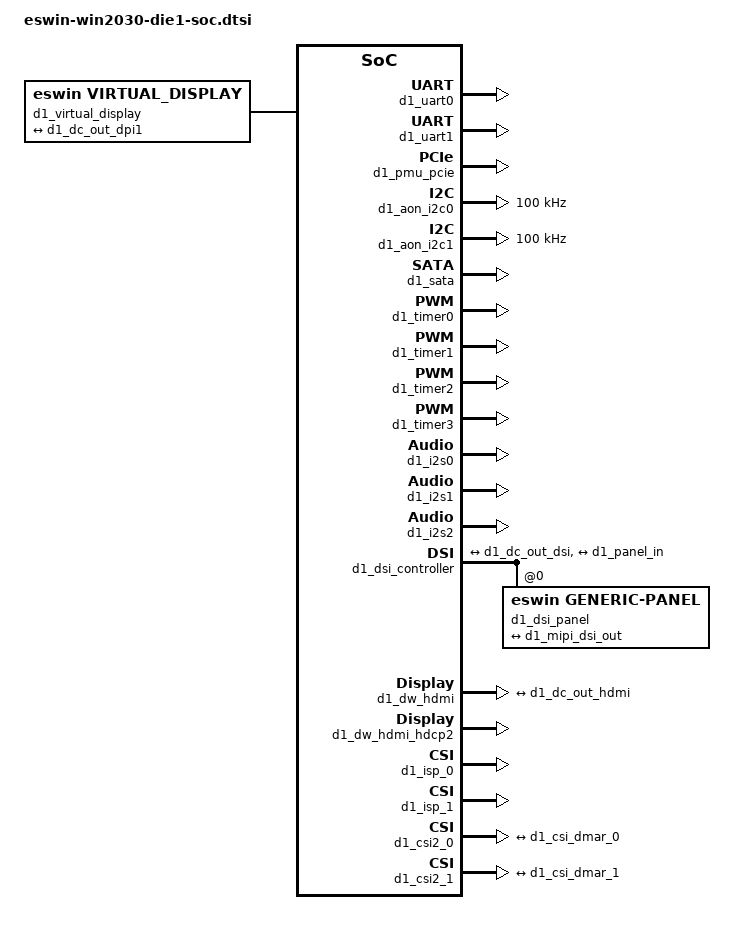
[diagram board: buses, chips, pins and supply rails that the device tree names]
// SPDX-License-Identifier: GPL-2.0
/*
 * Device Tree Include file for Die1 System peripherals of Eswin EIC770x family SoC.
 *
 * Copyright 2024, Beijing ESWIN Computing Technology Co., Ltd.. All rights reserved.
 * SPDX-License-Identifier: GPL-2.0
 *
 * This program is free software: you can redistribute it and/or modify
 * it under the terms of the GNU General Public License as published by
 * the Free Software Foundation, version 2.
 *
 * This program is distributed in the hope that it will be useful,
 * but WITHOUT ANY WARRANTY; without even the implied warranty of
 * MERCHANTABILITY or FITNESS FOR A PARTICULAR PURPOSE.  See the
 * GNU General Public License for more details.
 *
 * You should have received a copy of the GNU General Public License
 * along with this program.  If not, see <https://www.gnu.org/licenses/>.
 */

#include "eswin-win2030-arch-d2d.dtsi"


#include <dt-bindings/memory/eswin-win2030-sid.h>
#include <dt-bindings/mailbox/eswin-mailbox.h>
#include <dt-bindings/reset/eswin,win2030-syscrg.h>
#include <dt-bindings/clock/win2030-clock.h>
#include <dt-bindings/i2c/i2c.h>
#include <dt-bindings/interconnect/eswin,win2030.h>
#include <dt-bindings/power/eswin,eic770x-pmu.h>
#include <dt-bindings/thermal/thermal.h>

/ {
	d1_cpu_opp_table: opp-table1 {
		compatible = "operating-points-v2";
		opp-shared;

		opp-24000000 {
			opp-hz = /bits/ 64 <CLK_FREQ_24M>;
			opp-microvolt = <800000>;
			clock-latency-ns = <70000>;
		};
		opp-100000000 {
			opp-hz = /bits/ 64 <CLK_FREQ_100M>;
			opp-microvolt = <800000>;
			clock-latency-ns = <70000>;
		};
		opp-200000000 {
			opp-hz = /bits/ 64 <CLK_FREQ_200M>;
			opp-microvolt = <800000>;
			clock-latency-ns = <70000>;
		};
		opp-400000000 {
			opp-hz = /bits/ 64 <CLK_FREQ_400M>;
			opp-microvolt = <800000>;
			clock-latency-ns = <70000>;
		};
		opp-500000000 {
			opp-hz = /bits/ 64 <CLK_FREQ_500M>;
			opp-microvolt = <800000>;
			clock-latency-ns = <70000>;
		};
		opp-600000000 {
			opp-hz = /bits/ 64 <CLK_FREQ_600M>;
			opp-microvolt = <800000>;
			clock-latency-ns = <70000>;
		};
		opp-700000000 {
			opp-hz = /bits/ 64 <CLK_FREQ_700M>;
			opp-microvolt = <800000>;
			clock-latency-ns = <70000>;
		};
		opp-800000000 {
			opp-hz = /bits/ 64 <CLK_FREQ_800M>;
			opp-microvolt = <800000>;
			clock-latency-ns = <70000>;
		};
		opp-900000000 {
			opp-hz = /bits/ 64 <CLK_FREQ_900M>;
			opp-microvolt = <800000>;
			clock-latency-ns = <70000>;
		};
		opp-1000000000 {
			opp-hz = /bits/ 64 <CLK_FREQ_1000M>;
			opp-microvolt = <800000>;
			clock-latency-ns = <70000>;
		};
		opp-1200000000 {
			opp-hz = /bits/ 64 <CLK_FREQ_1200M>;
			opp-microvolt = <800000>;
			clock-latency-ns = <70000>;
		};
		opp-1300000000 {
			opp-hz = /bits/ 64 <CLK_FREQ_1300M>;
			opp-microvolt = <800000>;
			clock-latency-ns = <70000>;
		};
		opp-1400000000 {
			opp-hz = /bits/ 64 <CLK_FREQ_1400M>;
			opp-microvolt = <800000>;
			clock-latency-ns = <70000>;
		};
	};

	thermal-zones {
		d1_thermal0 {
			polling-delay-passive = <500>; /*ms*/
			polling-delay = <5000>; /*ms*/
			sustainable-power = <1200>; /*mW*/
			thermal-sensors = <&d1_pvt0>;

			trips {
				d1_threshold: trip-point0 {
					temperature = <60000>; /* DC*1000 */
					hysteresis = <1000>; /* DC*1000 */
					type = "passive";
				};
				d1_target: trip-point1 {
					temperature = <70000>;
					hysteresis = <1000>;
					type = "passive";
				};
				d1_crit: trip-point2 {
					temperature     = <110000>;
					hysteresis      = <0>;
					type            = "critical";
				};
			};

			cooling-maps {
				map0 {
					trip = <&d1_target>;
					contribution = <1024>;
					cooling-device =
						<&cpu_4 THERMAL_NO_LIMIT THERMAL_NO_LIMIT>,
						<&cpu_5 THERMAL_NO_LIMIT THERMAL_NO_LIMIT>,
						<&cpu_6 THERMAL_NO_LIMIT THERMAL_NO_LIMIT>,
						<&cpu_7 THERMAL_NO_LIMIT THERMAL_NO_LIMIT>;
				};
				map1 {
					trip = <&d1_target>;
					contribution = <1024>; /*TBD*/
					cooling-device = <&d1_npu THERMAL_NO_LIMIT THERMAL_NO_LIMIT>;
				};
				map2 {
					trip = <&d1_target>;
					contribution = <1024>; /*TBD*/
					cooling-device = <&d1_gpu THERMAL_NO_LIMIT THERMAL_NO_LIMIT>;
				};
			};
		};
	};
};

&SOC {
		d1_uart0: serial@0x70900000 {
			compatible = "snps,dw-apb-uart";
			reg = <0x0 0x70900000 0x0 0x10000>;
			clock-frequency = <LSPCLK_FREQ>;
			interrupt-parent = <&plic1>;
			interrupts = <UART0_INT>;
			reg-shift = <2>;
			reg-io-width = <4>;
			numa-node-id = <1>;
		};

		d1_uart1: serial@0x70910000 {
			compatible = "snps,dw-apb-uart";
			reg = <0x0 0x70910000 0x0 0x10000>;
			clock-frequency = <LSPCLK_FREQ>;
			interrupt-parent = <&plic1>;
			interrupts = <UART1_INT>;
			reg-shift = <2>;
			reg-io-width = <4>;
			numa-node-id = <1>;
		};

		d1_uart2: serial@0x70920000 {
			compatible = "snps,dw-apb-uart";
			reg = <0x0 0x70920000 0x0 0x10000>;
			clock-frequency = <LSPCLK_FREQ>;
			interrupt-parent = <&plic1>;
			interrupts = <UART2_INT>;
			reg-shift = <2>;
			reg-io-width = <4>;
			numa-node-id = <1>;
			status = "disabled";
		};

		d1_uart3: serial@0x70930000 {
			compatible = "snps,dw-apb-uart";
			reg = <0x0 0x70930000 0x0 0x10000>;
			clock-frequency = <LSPCLK_FREQ>;
			interrupt-parent = <&plic1>;
			interrupts = <UART3_INT>;
			reg-shift = <2>;
			reg-io-width = <4>;
			numa-node-id = <1>;
			status = "disabled";
		};

		d1_uart4: serial@0x70940000 {
			compatible = "snps,dw-apb-uart";
			reg = <0x0 0x70940000 0x0 0x10000>;
			clock-frequency = <LSPCLK_FREQ>;
			interrupt-parent = <&plic1>;
			interrupts = <UART4_INT>;
			reg-shift = <2>;
			reg-io-width = <4>;
			numa-node-id = <1>;
			status = "disabled";
		};

		d1_sys_con: scu_sys_con@0x71810000 {
			compatible = "eswin,win2030-scu-sys-con", "syscon";
			#syscon-cells = <2>;
			#size-cells = <2>;
			reg = <0x0 0x71810000 0x0 0x8000>;
			numa-node-id = <1>;
			d1_noc_wdt:noc@71810324 {
				compatible = "eswin,win2030-noc-wdt";
				interrupt-parent = <&plic1>;
				interrupts = <392>, <393>, <394>, <395>,
						<396>, <397>, <398>, <399>, <400>,
						<401>, <402>, <403>, <404>, <405>,
						<406>, <407>, <408>, <409>, <410>,
						<411>, <412>, <413>, <414>, <415>,
						<416>, <417>, <418>, <419>, <420>,
						<421>, <422>, <423>, <424>, <425>,
						<426>;
				eswin,syscrg_csr = <&d1_sys_crg 0x100 0xffff>; //timeout paramerter
			};
		};

		d1_sys_crg: sys-crg@71828000 {
			compatible = "eswin,win2030-sys-crg", "syscon", "simple-mfd";
			reg = <0x000000 0x71828000 0x000000 0x80000>;
			numa-node-id = <1>;
			d1_reset: reset-controller {
				compatible = "eswin,win2030-reset";
				#reset-cells = <2>;
			};
			d1_clock: clock-controller {
				compatible = "eswin,win2030-clock";
				#clock-cells = <1>;
			};
		};

		d1_hsp_sp_csr: hsp_sp_top_csr@0x70440000 {
			compatible = "eswin,win2030-hsp-sp-csr", "syscon";
			#size-cells = <2>;
			reg = <0x0 0x70440000 0x0 0x2000>;
		};

		smmu1: iommu@70c00000 {
			compatible = "arm,smmu-v3";
			reg = <0x0 0x70c00000 0x0 0x100000>;
			eswin,syscfg = <&d1_sys_con 0x3fc>;
			interrupt-parent = <&plic1>;
			interrupts = <356>,
				<360>,
				<357>,
				<358>;
			interrupt-names = "eventq", "gerror", "priq", "cmdq-sync";
			#iommu-cells = <1>;
			resets = <&d1_reset TCU_RST_CTRL SW_TCU_AXI_RSTN>,
				<&d1_reset TCU_RST_CTRL SW_TCU_CFG_RSTN>,
				<&d1_reset TCU_RST_CTRL TBU_RSTN_0>,
				<&d1_reset TCU_RST_CTRL TBU_RSTN_1>,
				<&d1_reset TCU_RST_CTRL TBU_RSTN_2>,
				<&d1_reset TCU_RST_CTRL TBU_RSTN_3>,
				<&d1_reset TCU_RST_CTRL TBU_RSTN_4>,
				<&d1_reset TCU_RST_CTRL TBU_RSTN_5>,
				<&d1_reset TCU_RST_CTRL TBU_RSTN_6>,
				<&d1_reset TCU_RST_CTRL TBU_RSTN_7>;
			reset-names = "axi_rst", "cfg_rst", "tbu0_rst", "tbu1_rst", "tbu2_rst", "tbu3_rst",
				"tbu4_rst", "tbu5_rst", "tbu6_rst", "tbu7_rst";
			status = "disabled";
			numa-node-id = <1>;
			dma-noncoherent;
		};

		smmu_pmu1: pmu@70c02000 {
			compatible = "arm,smmu-v3-pmcg";
			reg = <0x0 0x70c02000 0x0 0x1000>,
					<0x0 0x70c22000 0x0 0x1000>;
			eswin,syscfg = <&d1_sys_con 0x3fc>;
			interrupt-parent = <&plic1>;
			interrupts = <363>;
			status = "disabled";
			numa-node-id = <1>;
			dma-noncoherent;
		};

		dev_foo_for_die1_mapping: E21@2 {
			compatible = "riscv,dev-foo-die1";
			#size-cells = <2>;
			dma-ranges = <0x0 0x20000000 0x0 0xc0000000 0x0 0x40000000>;
			iommus = <&smmu1 WIN2030_SID_DEV_FOO_FOR_DIE1>;
			status = "disabled";
			numa-node-id = <1>;
			dma-noncoherent;
		};

		d1_pmu: power-controller@71808000 {
			#address-cells = <1>;
			#size-cells = <0>;
			compatible = "eswin,win2030-pmu-controller";
			reg = <0x0 0x71808000 0x0 0x8000>;
			numa-node-id = <1>;

			d1_pmu_pcie: win2030-pmu-controller-port@0 {
				compatible = "eswin,win2030-pmu-controller-port";
				reg_base = <0x0>;
				power_status = <1>;
				power_delay = <6 6 3 3>;
				clock_delay = <4 2 2 2>;
				reset_delay = <2 4 2 2>;
				clamp_delay = <3 3 2 2>;
				label = "D1_PCIE";
			};
			d1_pmu_dsp1: win2030-pmu-controller-port@40 {
				compatible = "eswin,win2030-pmu-controller-port";
				reg_base = <0x40>;
				power_status = <0>;
				power_delay = <6 6 3 3>;
				clock_delay = <4 2 2 2>;
				reset_delay = <2 4 2 2>;
				clamp_delay = <3 3 2 2>;
				label = "D1_DSP1";
			};
			d1_pmu_vi: win2030-pmu-controller-port@80 {
				compatible = "eswin,win2030-pmu-controller-port";
				reg_base = <0x80>;
				power_status = <1>;
				power_delay = <6 6 3 3>;
				clock_delay = <4 2 2 2>;
				reset_delay = <2 4 2 2>;
				clamp_delay = <3 3 2 2>;
				label = "D1_VI";
			};
			d1_pmu_vo: win2030-pmu-controller-port@c0 {
				compatible = "eswin,win2030-pmu-controller-port";
				reg_base = <0xc0>;
				power_status = <0>;
				power_delay = <6 6 3 3>;
				clock_delay = <4 2 2 2>;
				reset_delay = <2 4 2 2>;
				clamp_delay = <3 3 2 2>;
				label = "D1_VO";
			};
			d1_pmu_codec: win2030-pmu-controller-port@140 {
				compatible = "eswin,win2030-pmu-controller-port";
				reg_base = <0x140>;
				power_status = <0>;
				power_delay = <6 6 3 3>;
				clock_delay = <4 2 2 2>;
				reset_delay = <2 4 2 2>;
				clamp_delay = <3 3 2 2>;
				label = "D1_CODEC";
			};
			d1_pmu_dsp2: win2030-pmu-controller-port@200 {
				compatible = "eswin,win2030-pmu-controller-port";
				reg_base = <0x200>;
				power_status = <0>;
				power_delay = <6 6 3 3>;
				clock_delay = <4 2 2 2>;
				reset_delay = <2 4 2 2>;
				clamp_delay = <3 3 2 2>;
				label = "D1_DSP2";
			};
			d1_pmu_dsp3: win2030-pmu-controller-port@240 {
				compatible = "eswin,win2030-pmu-controller-port";
				reg_base = <0x240>;
				power_status = <0>;
				power_delay = <6 6 3 3>;
				clock_delay = <4 2 2 2>;
				reset_delay = <2 4 2 2>;
				clamp_delay = <3 3 2 2>;
				label = "D1_DSP3";
			};
		};

		d1_dmac0: dma-controller-hsp@0x70430000 {
			compatible = "eswin,eic770x-axi-dma";
			reg = <0x0 0x70430000 0x0 0x10000>;
			interrupt-parent = <&plic1>;
			interrupts = <57>;
			#dma-cells = <2>; // change dma-cells value <1> to <2>, to support peripheral selection dma-controller,See the parameter dmas for details;
			clocks = <&d1_clock WIN2030_CLK_HSP_DMA0_CLK>,
					 <&d1_clock WIN2030_CLK_HSP_DMA0_CLK_TEST>;
			clock-names = "core-clk", "cfgr-clk";
			resets = <&d1_reset HSPDMA_RST_CTRL SW_HSP_DMA0_RSTN>,
				<&d1_reset HSPDMA_RST_CTRL SW_HSP_DMA_PRSTN>;
			reset-names = "arst", "prst";
			dma-channels = <12>;
			snps,dma-masters = <1>;
			snps,priority = <0 1 2 3 4 5 6 7 8 9 10 11>;
			snps,data-width = <2>;
			snps,block-size = <0x80000 0x80000 0x80000 0x80000 0x80000 0x80000 0x80000 0x80000 0x80000 0x80000 0x80000 0x80000>;
			snps,axi-max-burst-len = <16>;
			snps,max-msize = <64>;
			iommus = <&smmu1 WIN2030_SID_DMA0>;
			tbus = <WIN2030_TBUID_DMA0>;
			eswin,hsp_sp_csr = <&d1_hsp_sp_csr 0x104c>;
			eswin,syscfg = <&d1_sys_con DMA1_SID_REG_OFFSET 0x370>;
			numa-node-id = <1>;
			dma-noncoherent;
		};

		d1_aon_dmac: dma-controller-aon@0x718c0000 {
			compatible = "eswin,eic770x-axi-dma";
			reg = <0x0 0x718c0000 0x0 0x10000>;
			interrupt-parent = <&plic1>;
			interrupts = <289>;
			#dma-cells = <2>; // change dma-cells value <1> to <2>, to support peripheral selection dma-controller,See the parameter dmas for details;
			clocks = <&d1_clock WIN2030_CLK_AONDMA_ACLK>,
				 <&d1_clock WIN2030_CLK_AONDMA_CFG>;
			clock-names = "core-clk", "cfgr-clk";
			resets = <&d1_reset DMA1_RST_CTRL SW_DMA1_ARSTN>,
				<&d1_reset DMA1_RST_CTRL SW_DMA1_HRSTN>;
			reset-names = "arst", "prst";
			dma-channels = <16>;
			snps,dma-masters = <2>;
			snps,priority = <0 1 2 3 4 5 6 7 8 9 10 11 12 13 14 15>;
			snps,data-width = <3>;
			snps,block-size = <0x80000 0x80000 0x80000 0x80000 0x80000 0x80000 0x80000 0x80000 0x80000 0x80000 0x80000 0x80000 0x80000 0x80000 0x80000 0x80000>;
			snps,axi-max-burst-len = <32>;
			snps,max-msize = <64>;
			#size-cells = <2>;
			#address-cells = <2>;
			dma-ranges = <0x0 0x80000000 0x0 0x80000000 0x100 0x0>;
			iommus = <&smmu1 WIN2030_SID_DMA1>;
			tbus = <WIN2030_TBUID_DMA1>;
			eswin,syscfg = <&d1_sys_con DMA1_SID_REG_OFFSET 0x370>;
			numa-node-id = <1>;
			dma-noncoherent;
		};
		noc {
			compatible = "eswin,noc","simple-bus";
			#address-cells = <2>;
			#size-cells = <2>;
			ranges;
			#include "eswin-win2030-die1-noc.dtsi"
		};
		vdec1: video-decoder1@70100000 {
			compatible = "eswin,video-decoder1";
			clocks = <&d1_clock WIN2030_CLK_VC_ACLK>,
					 <&d1_clock WIN2030_CLK_VC_CFG_CLK>,
					 <&d1_clock WIN2030_CLK_VC_JD_CLK>,
					 <&d1_clock WIN2030_CLK_VC_VD_CLK>,
					 <&d1_clock WIN2030_MUX_U_VCACLK_ROOT_2MUX1_GFREE>,
					 <&d1_clock WIN2030_SPLL0_FOUT1>,
					 <&d1_clock WIN2030_SPLL2_FOUT1>,
					 <&d1_clock WIN2030_CLK_VC_JD_PCLK>,
					 <&d1_clock WIN2030_CLK_VC_VD_PCLK>,
					 <&d1_clock WIN2030_CLK_VC_MON_PCLK>;
			clock-names = "aclk", "cfg_clk", "jd_clk", "vd_clk", "vc_mux", "spll0_fout1", "spll2_fout1", "jd_pclk", "vd_pclk", "mon_pclk";
			resets = <&d1_reset VC_RST_CTRL SW_VC_AXI_RSTN>,
					 <&d1_reset VC_RST_CTRL SW_VC_CFG_RSTN>,
					 <&d1_reset VC_RST_CTRL SW_VC_MONCFG_RSTN>,
					 <&d1_reset JD_RST_CTRL SW_JD_CFG_RSTN>,
					 <&d1_reset JD_RST_CTRL SW_JD_AXI_RSTN>,
					 <&d1_reset VD_RST_CTRL SW_VD_CFG_RSTN>,
					 <&d1_reset VD_RST_CTRL SW_VD_AXI_RSTN>;
			reset-names = "axi", "cfg", "moncfg", "jd_cfg", "jd_axi", "vd_cfg", "vd_axi";
			eswin,syscfg = <&d1_sys_con 0x0 0x4>;

			vcmd-core = <0 0x6c>;
			axife-core = <0x200 0x100>;
			vdec-core = <0x800 0xc00>;
			interrupt-parent = <&plic1>;
			#size-cells = <2>;
			dma-ranges = <0x0 0x0 0x0 0x80000000 0x200 0x0>;
			iommus = <&smmu1 WIN2030_SID_VDEC>;
			vccsr-reg = <0x0 0x701c0000 0x0 0x1000>;
			numa-node-id = <1>;
			tbus = <WIN2030_TBUID_VDEC>, <WIN2030_TBUID_JDEC>;
			dma-noncoherent;

			vdec_1: vdec1@70100000 {
				core-name = "video-dec0";
				base-addr = <0x70100000>;
				interrupts = <236>;
			};

			jdec_1: jdec1@70120000 {
				core-name = "jpeg-dec0";
				base-addr = <0x70120000>;
				interrupts = <237>;
			};
		};

		venc1: video-encoder@70110000 {
			compatible = "eswin,video-encoder1";
			clocks = <&d1_clock WIN2030_CLK_VC_ACLK>,
					 <&d1_clock WIN2030_CLK_VC_CFG_CLK>,
					 <&d1_clock WIN2030_CLK_VC_JE_CLK>,
					 <&d1_clock WIN2030_CLK_VC_VE_CLK>,
					 <&d1_clock WIN2030_MUX_U_VCACLK_ROOT_2MUX1_GFREE>,
					 <&d1_clock WIN2030_SPLL0_FOUT1>,
					 <&d1_clock WIN2030_SPLL2_FOUT1>,
					 <&d1_clock WIN2030_CLK_VC_JE_PCLK>,
					 <&d1_clock WIN2030_CLK_VC_VE_PCLK>,
					 <&d1_clock WIN2030_CLK_VC_MON_PCLK>;
			clock-names = "aclk", "cfg_clk", "je_clk", "ve_clk", "vc_mux", "spll0_fout1", "spll2_fout1", "je_pclk", "ve_pclk", "mon_pclk";
			resets = <&d1_reset VC_RST_CTRL SW_VC_AXI_RSTN>,
					 <&d1_reset VC_RST_CTRL SW_VC_CFG_RSTN>,
					 <&d1_reset VC_RST_CTRL SW_VC_MONCFG_RSTN>,
					 <&d1_reset JE_RST_CTRL SW_JE_CFG_RSTN>,
					 <&d1_reset JE_RST_CTRL SW_JE_AXI_RSTN>,
					 <&d1_reset VE_RST_CTRL SW_VE_CFG_RSTN>,
					 <&d1_reset VE_RST_CTRL SW_VE_AXI_RSTN>;
			reset-names = "axi", "cfg", "moncfg", "je_cfg", "je_axi", "ve_cfg", "ve_axi";
			eswin,syscfg = <&d1_sys_con 0x0 0x4>;

			vcmd-core = <0 0x6c>;
			axife-core = <0x2000 0x7d0>;
			venc-core = <0x1000 0x87c>;
			interrupt-parent = <&plic1>;
			#size-cells = <2>;
			dma-ranges = <0x0 0x0 0x0 0x80000000 0x200 0x0>;
			iommus = <&smmu1 WIN2030_SID_VENC>;
			vccsr-reg = <0x0 0x701c0000 0x0 0x1000>;
			numa-node-id = <1>;
			dma-noncoherent;

			venc_1: venc0@70110000 {
				core-name = "video-enc0";
				base-addr = <0x70110000>;
				interrupts = <229>;
				tbus = <WIN2030_TBUID_VENC>;
			};

			jenc_1: jenc0@70130000 {
				core-name = "jpeg-enc0";
				base-addr = <0x70130000>;
				interrupts = <232>;
				tbus = <WIN2030_TBUID_JENC>;
			};
		};
		/*mailbox between u84 & scpu*/
		d1_mbox0: mbox@70a00000 {
			compatible = "eswin,win2030-mailbox";
			reg = <0 (ESWIN_MAILBOX_U84_TO_SCPU_REG_BASE + 0x20000000) 0 0x10000>,
				  <0 (ESWIN_MAILBOX_SCPU_TO_U84_REG_BASE + 0x20000000) 0 0x10000>;
			interrupt-parent = <&plic1>;
			interrupts = <117>;
			#mbox-cells = <1>;
			clocks = <&d1_clock WIN2030_CLK_MAILBOX_0>,
				<&d1_clock WIN2030_CLK_MAILBOX_1>;
			clock-names = "pclk_mailbox_host", "pclk_mailbox_device";
			resets = <&d1_reset MBOX_RST_CTRL SW_MBOX_RST_N_0>,
				<&d1_reset MBOX_RST_CTRL SW_MBOX_RST_N_1>;
			reset-names = "rst", "rst_device";
			lock-bit = <ESWIN_MAILBOX_WR_LOCK_BIT_U84>;
			irq-bit = <ESWIN_MAIBOX_SCPU_IRQ_BIT>;
			dma-noncoherent;
		};

		/*mailbox between u84 & lpcpu*/
		d1_mbox1: mbox@70a20000 {
			compatible = "eswin,win2030-mailbox";
			reg = <0 (ESWIN_MAILBOX_U84_TO_LPCPU_REG_BASE + 0x20000000) 0 0x10000>,
				  <0 (ESWIN_MAILBOX_LPCPU_TO_U84_REG_BASE + 0x20000000) 0 0x10000>;
			interrupt-parent = <&plic1>;
			interrupts = <119>;
			#mbox-cells = <1>;
			clocks = <&d1_clock WIN2030_CLK_MAILBOX_2>,
				<&d1_clock WIN2030_CLK_MAILBOX_3>;
			resets = <&d1_reset MBOX_RST_CTRL SW_MBOX_RST_N_2>,
				<&d1_reset MBOX_RST_CTRL SW_MBOX_RST_N_3>;
			reset-names = "rst", "rst_device";
			clock-names = "pclk_mailbox_host", "pclk_mailbox_device";
			lock-bit = <ESWIN_MAILBOX_WR_LOCK_BIT_U84>;
			irq-bit  = <ESWIN_MAIBOX_LPCPU_IRQ_BIT>;
			dma-noncoherent;
		};

		/*mailbox between u84 & npu_0*/
		d1_mbox2: mbox@70a40000 {
			compatible = "eswin,npu1-mailbox";
			reg = <0 (ESWIN_MAILBOX_U84_TO_NPU_0_REG_BASE + 0x20000000) 0 0x10000>,
				  <0 (ESWIN_MAILBOX_NPU_0_TO_U84_REG_BASE + 0x20000000) 0 0x10000>;
			interrupt-parent = <&plic1>;
			interrupts = <121>;
			#mbox-cells = <1>;
			clocks = <&d1_clock WIN2030_CLK_MAILBOX_4>,
				<&d1_clock WIN2030_CLK_MAILBOX_5>;
			clock-names = "pclk_mailbox_host", "pclk_mailbox_device";
			resets = <&d1_reset MBOX_RST_CTRL SW_MBOX_RST_N_4>,
				<&d1_reset MBOX_RST_CTRL SW_MBOX_RST_N_5>;
			reset-names = "rst", "rst_device";
			lock-bit = <ESWIN_MAILBOX_WR_LOCK_BIT_U84>;
			irq-bit  = <ESWIN_MAIBOX_NPU_0_IRQ_BIT>;
			dma-noncoherent;
		};

		/*mailbox between u84 & npu_1*/
		d1_mbox3: mbox@70a60000 {
			compatible = "eswin,win2030-mailbox";
			reg = <0 (ESWIN_MAILBOX_U84_TO_NPU_1_REG_BASE + 0x20000000) 0 0x10000>,
				  <0 (ESWIN_MAILBOX_NP1_0_TO_U84_REG_BASE + 0x20000000) 0 0x10000>;
			interrupt-parent = <&plic1>;
			interrupts = <123>;
			#mbox-cells = <1>;
			clocks = <&d1_clock WIN2030_CLK_MAILBOX_6>,
				<&d1_clock WIN2030_CLK_MAILBOX_7>;
			clock-names = "pclk_mailbox_host", "pclk_mailbox_device";
			resets = <&d1_reset MBOX_RST_CTRL SW_MBOX_RST_N_6>,
				<&d1_reset MBOX_RST_CTRL SW_MBOX_RST_N_7>;
			reset-names = "rst", "rst_device";
			lock-bit = <ESWIN_MAILBOX_WR_LOCK_BIT_U84>;
			irq-bit  = <ESWIN_MAIBOX_NPU_1_IRQ_BIT>;
			dma-noncoherent;
		};

		/*mailbox between u84 & dsp_0*/
		d1_mbox4: mbox@70a80000 {
			compatible = "eswin,dsp0-mailbox";
			reg = <0 (ESWIN_MAILBOX_U84_TO_DSP_0_REG_BASE + 0x20000000) 0 0x10000>,
				  <0 (ESWIN_MAILBOX_DSP_0_TO_U84_REG_BASE + 0x20000000) 0 0x10000>;
			interrupt-parent = <&plic1>;
			interrupts = <125>;
			#mbox-cells = <1>;
			clocks = <&d1_clock WIN2030_CLK_MAILBOX_8>,
				<&d1_clock WIN2030_CLK_MAILBOX_9>;
			clock-names = "pclk_mailbox_host", "pclk_mailbox_device";
			resets = <&d1_reset MBOX_RST_CTRL SW_MBOX_RST_N_8>,
				<&d1_reset MBOX_RST_CTRL SW_MBOX_RST_N_9>;
			reset-names = "rst", "rst_device";
			lock-bit = <ESWIN_MAILBOX_WR_LOCK_BIT_U84>;
			irq-bit  = <ESWIN_MAIBOX_DSP_0_IRQ_BIT>;
			dma-noncoherent;
		};

		/*mailbox between u84 & dsp_1*/
		d1_mbox5: mbox@70aa0000 {
			compatible = "eswin,dsp1-mailbox";
			reg = <0 (ESWIN_MAILBOX_U84_TO_DSP_1_REG_BASE + 0x20000000) 0 0x10000>,
				  <0 (ESWIN_MAILBOX_DSP_1_TO_U84_REG_BASE + 0x20000000) 0 0x10000>;
			interrupt-parent = <&plic1>;
			interrupts = <127>;
			#mbox-cells = <1>;
			clocks = <&d1_clock WIN2030_CLK_MAILBOX_10>,
				<&d1_clock WIN2030_CLK_MAILBOX_11>;
			clock-names = "pclk_mailbox_host", "pclk_mailbox_device";
			resets = <&d1_reset MBOX_RST_CTRL SW_MBOX_RST_N_10>,
				<&d1_reset MBOX_RST_CTRL SW_MBOX_RST_N_11>;
			reset-names = "rst", "rst_device";
			lock-bit = <ESWIN_MAILBOX_WR_LOCK_BIT_U84>;
			irq-bit  = <ESWIN_MAIBOX_DSP_1_IRQ_BIT>;
			dma-noncoherent;
		};

		/*mailbox between u84 & dsp_2*/
		d1_mbox6: mbox@70ac0000 {
			compatible = "eswin,dsp2-mailbox";
			reg = <0 (ESWIN_MAILBOX_U84_TO_DSP_2_REG_BASE + 0x20000000) 0 0x10000>,
				  <0 (ESWIN_MAILBOX_DSP_2_TO_U84_REG_BASE + 0x20000000) 0 0x10000>;
			interrupt-parent = <&plic1>;
			interrupts = <129>;
			#mbox-cells = <1>;
			clocks = <&d1_clock WIN2030_CLK_MAILBOX_12>,
				<&d1_clock WIN2030_CLK_MAILBOX_13>;
			clock-names = "pclk_mailbox_host", "pclk_mailbox_device";
			resets = <&d1_reset MBOX_RST_CTRL SW_MBOX_RST_N_12>,
				<&d1_reset MBOX_RST_CTRL SW_MBOX_RST_N_13>;
			reset-names = "rst", "rst_device";
			lock-bit = <ESWIN_MAILBOX_WR_LOCK_BIT_U84>;
			irq-bit  = <ESWIN_MAIBOX_DSP_2_IRQ_BIT>;
			dma-noncoherent;
		};

		/*mailbox between u84 & dsp_3*/
		d1_mbox7: mbox@70ae0000 {
			compatible = "eswin,dsp3-mailbox";
			reg = <0 (ESWIN_MAILBOX_U84_TO_DSP_3_REG_BASE + 0x20000000) 0 0x10000>,
				  <0 (ESWIN_MAILBOX_DSP_3_TO_U84_REG_BASE + 0x20000000) 0 0x10000>;
			interrupt-parent = <&plic1>;
			interrupts = <131>;
			#mbox-cells = <1>;
			clocks = <&d1_clock WIN2030_CLK_MAILBOX_14>,
				<&d1_clock WIN2030_CLK_MAILBOX_15>;
			clock-names = "pclk_mailbox_host", "pclk_mailbox_device";
			resets = <&d1_reset MBOX_RST_CTRL SW_MBOX_RST_N_14>,
				<&d1_reset MBOX_RST_CTRL SW_MBOX_RST_N_15>;
			reset-names = "rst", "rst_device";
			lock-bit = <ESWIN_MAILBOX_WR_LOCK_BIT_U84>;
			irq-bit  = <ESWIN_MAIBOX_DSP_3_IRQ_BIT>;
			dma-noncoherent;
		};

		d1_ipc_scpu:ipc@1 {
			compatible = "eswin,win2030-ipc";
			#size-cells = <2>;
			dma-ranges = <0x0 0x80000000 0x0 0xc0000000 0x0 0x80000000>;
			iommus = <&smmu1 WIN2030_SID_SCPU>, <&smmu1 WIN2030_SID_CRYPT>;
			eswin,syscfg = <&d1_sys_con SCPU_SID_REG_OFFSET 0>,
			               <&d1_sys_con CRYPT_SID_REG_OFFSET 0>;
			mboxes = <&d1_mbox0 0>;
			mbox-names = "u84_scpu";
			numa-node-id = <1>;
			dma-noncoherent;
		};

		d1_lpcpu:lpcpu@1 {
			compatible = "eswin,win2030-lpcpu";
			/* fw-region = <&lpcpu1_reserved>; */
			clocks = <&d1_clock WIN2030_CLK_CLK_LPCPU_CORE>,
					<&d1_clock WIN2030_CLK_CLK_LPCPU_BUS>;
			clock-names = "core_clk", "bus_clk";

			reset-names = "core_rst", "bus_rst", "dbg_rst";
			resets = <&d1_reset LPCPU_RST_CTRL SW_LPCPU_CORE_RSTN>,
					<&d1_reset LPCPU_RST_CTRL SW_LPCPU_BUS_RSTN>,
					<&d1_reset LPCPU_RST_CTRL SW_LPCPU_DBG_RSTN>;
			#size-cells = <2>;

			dma-ranges = <0x0 0xb0000000 0x0 0xc0000000 0x0 0x50000000>;
			iommus = <&smmu1 WIN2030_SID_LCPU>;
			eswin,syscfg = <&d1_sys_con LCPU_SID_REG_OFFSET 0>;
			tbus = <WIN2030_TBUID_LPCPU>;
			mboxes = <&d1_mbox1 0>;
			mbox-names = "u84_lpcpu";
			numa-node-id = <1>;
			status = "disabled";
			dma-noncoherent;
		};

		d1_pvt0: pvt@0x70b00000 {
			compatible = "eswin,eswin-pvt-cpu";
			clocks = <&d1_clock WIN2030_CLK_PVT_CLK_0>;
			clock-names = "pvt_clk";
			resets = <&d1_reset PVT_RST_CTRL SW_PVT_RST_N_0>;
			reset-names = "pvt_rst";
			#address-cells = <1>;
			#size-cells = <0>;
			reg = <0x0 0x70b00000 0x0 0x10000>;
			interrupts = <349>;
			interrupt-parent = <&plic1>;
			#thermal-sensor-cells = <0>;
			status = "disabled";
			label = "d1_pvt0";
		};
		d1_pvt1: pvt@0x72360000 {
			compatible = "eswin,eswin-pvt-ddr";
			clocks = <&d1_clock WIN2030_CLK_PVT_CLK_1>;
			clock-names = "pvt_clk";
			resets = <&d1_reset PVT_RST_CTRL SW_PVT_RST_N_1>;
			reset-names = "pvt_rst";
			#address-cells = <1>;
			#size-cells = <0>;
			reg = <0x0 0x72360000 0x0 0x20000>;
			interrupts = <350>;
			interrupt-parent = <&plic1>;
			status = "disabled";
			label = "d1_pvt1";
		};

		d1_fan_control: fan_control@70b50000 {
			compatible = "eswin-fan-control";
			reg = <0x0 0x70b50000 0x0 0x10000>;
			clocks = <&d1_clock WIN2030_CLK_LSP_FAN_PCLK>;
			clock-names = "pclk";
			resets = <&d1_reset FAN_RST_CTRL SW_FAN_RST_N>;
			reset-names = "fan_rst";
			interrupt-parent = <&plic1>;
			interrupt-names = "fanirq";
			interrupts = <354>;
			pulses-per-revolution = <1>;
			pwm-minimum-period = <1000>;
			pwms = <&d1_pwm0 0 100000>;
			status = "disabled";
			label = "d1_fan_control";
		};

		d1_i2c0: i2c@70950000 {
				compatible = "snps,designware-i2c";
				clock-frequency = <I2C_BITRATE_STANDARD>;
				clocks = <&d1_clock WIN2030_CLK_LSP_I2C0_PCLK>;
				clock-names = "pclk";
				resets = <&d1_reset I2C_RST_CTRL SW_I2C_RST_N_0>;
				reset-names = "rst";
				#address-cells = <1>;
				#size-cells = <0>;
				reg = <0x0 0x70950000 0x0 0x10000>;
				interrupts = <105>;
				interrupt-parent = <&plic1>;
				status = "disabled";
				eswin,i2c_dma = <&d1_aon_dmac>;
				dma-names = "rx", "tx";
				/*
				* dmas : DMA specifiers
				* &d1_aon_dmac : dma controller
				* 24 : i2c0  aon dma handshake number
				* 6 : i2c0 dma controller sel bit in sys_son dma_cfg reg(offset 0x370)
				*/
				dmas = <&d1_aon_dmac 24 6>, <&d1_aon_dmac 25 6>;
		};
		d1_i2c1: i2c@70960000 {
				compatible = "snps,designware-i2c";
				clock-frequency = <I2C_BITRATE_STANDARD>;
				clocks = <&d1_clock WIN2030_CLK_LSP_I2C1_PCLK>;
				clock-names = "pclk";
				resets = <&d1_reset I2C_RST_CTRL SW_I2C_RST_N_1>;
				reset-names = "rst";
				#address-cells = <1>;
				#size-cells = <0>;
				reg = <0x0 0x70960000 0x0 0x10000>;
				interrupts = <106>;
				interrupt-parent = <&plic1>;
				status = "disabled";
		};
		d1_i2c2: i2c@70970000 {
				compatible = "snps,designware-i2c";
				clock-frequency = <I2C_BITRATE_STANDARD>;
				clocks = <&d1_clock WIN2030_CLK_LSP_I2C2_PCLK>;
				clock-names = "pclk";
				resets = <&d1_reset I2C_RST_CTRL SW_I2C_RST_N_2>;
				reset-names = "rst";
				#address-cells = <1>;
				#size-cells = <0>;
				reg = <0x0 0x70970000 0x0 0x10000>;
				interrupts = <107>;
				interrupt-parent = <&plic1>;
				status = "disabled";
		};
		d1_i2c3: i2c@70980000 {
				compatible = "snps,designware-i2c";
				clock-frequency = <I2C_BITRATE_STANDARD>;
				clocks = <&d1_clock WIN2030_CLK_LSP_I2C3_PCLK>;
				clock-names = "pclk";
				resets = <&d1_reset I2C_RST_CTRL SW_I2C_RST_N_3>;
				reset-names = "rst";
				#address-cells = <1>;
				#size-cells = <0>;
				reg = <0x0 0x70980000 0x0 0x10000>;
				interrupts = <108>;
				interrupt-parent = <&plic1>;
				status = "disabled";
		};
		d1_i2c4: i2c@70990000 {
				compatible = "snps,designware-i2c";
				clock-frequency = <I2C_BITRATE_STANDARD>;
				clocks = <&d1_clock WIN2030_CLK_LSP_I2C4_PCLK>;
				clock-names = "pclk";
				resets = <&d1_reset I2C_RST_CTRL SW_I2C_RST_N_4>;
				reset-names = "rst";
				#address-cells = <1>;
				#size-cells = <0>;
				reg = <0x0 0x70990000 0x0 0x10000>;
				interrupts = <109>;
				interrupt-parent = <&plic1>;
				status = "disabled";
		};
		d1_i2c5: i2c@709a0000 {
				compatible = "snps,designware-i2c";
				clock-frequency = <I2C_BITRATE_STANDARD>;
				clocks = <&d1_clock WIN2030_CLK_LSP_I2C5_PCLK>;
				clock-names = "pclk";
				resets = <&d1_reset I2C_RST_CTRL SW_I2C_RST_N_5>;
				reset-names = "rst";
				#address-cells = <1>;
				#size-cells = <0>;
				reg = <0x0 0x709a0000 0x0 0x10000>;
				interrupts = <110>;
				interrupt-parent = <&plic1>;
				status = "disabled";
		};
		d1_i2c6: i2c@709b0000 {
				compatible = "snps,designware-i2c";
				clock-frequency = <I2C_BITRATE_STANDARD>;
				clocks = <&d1_clock WIN2030_CLK_LSP_I2C6_PCLK>;
				clock-names = "pclk";
				resets = <&d1_reset I2C_RST_CTRL SW_I2C_RST_N_6>;
				reset-names = "rst";
				#address-cells = <1>;
				#size-cells = <0>;
				reg = <0x0 0x709b0000 0x0 0x10000>;
				interrupts = <111>;
				interrupt-parent = <&plic1>;
				status = "disabled";
		};
		d1_i2c7: i2c@709c0000 {
				compatible = "snps,designware-i2c";
				clock-frequency = <I2C_BITRATE_STANDARD>;
				clocks = <&d1_clock WIN2030_CLK_LSP_I2C7_PCLK>;
				clock-names = "pclk";
				resets = <&d1_reset I2C_RST_CTRL SW_I2C_RST_N_7>;
				reset-names = "rst";
				#address-cells = <1>;
				#size-cells = <0>;
				reg = <0x0 0x709c0000 0x0 0x10000>;
				interrupts = <112>;
				interrupt-parent = <&plic1>;
				status = "disabled";
		};
		d1_i2c8: i2c@709d0000 {
				compatible = "snps,designware-i2c";
				clock-frequency = <I2C_BITRATE_STANDARD>;
				clocks = <&d1_clock WIN2030_CLK_LSP_I2C8_PCLK>;
				clock-names = "pclk";
				resets = <&d1_reset I2C_RST_CTRL SW_I2C_RST_N_8>;
				reset-names = "rst";
				#address-cells = <1>;
				#size-cells = <0>;
				reg = <0x0 0x709d0000 0x0 0x10000>;
				interrupts = <113>;
				interrupt-parent = <&plic1>;
				status = "disabled";
		};
		d1_i2c9: i2c@709e0000 {
				compatible = "snps,designware-i2c";
				clock-frequency = <I2C_BITRATE_STANDARD>;
				clocks = <&d1_clock WIN2030_CLK_LSP_I2C9_PCLK>;
				clock-names = "pclk";
				resets = <&d1_reset I2C_RST_CTRL SW_I2C_RST_N_9>;
				reset-names = "rst";
				#address-cells = <1>;
				#size-cells = <0>;
				reg = <0x0 0x709e0000 0x0 0x10000>;
				interrupts = <114>;
				interrupt-parent = <&plic1>;
				status = "disabled";
		};

		d1_aon_i2c0: i2c@71830000 {
				compatible = "snps,designware-i2c";
				clock-frequency = <I2C_BITRATE_STANDARD>;
				clocks = <&d1_clock WIN2030_CLK_AON_I2C0_PCLK>;
				clock-names = "pclk";
				resets = <&d1_reset I2C0_RST_CTRL SW_I2C0_PRSTN>;
				reset-names = "rst";
				#address-cells = <1>;
				#size-cells = <0>;
				reg = <0x0 0x71830000 0x0 0x10000>;
				interrupts = <290>;
				interrupt-parent = <&plic1>;
				eswin,i2c_dma = <&d1_aon_dmac>;
				dma-names = "rx", "tx";
				/*
				* dmas : DMA specifiers
				* &d1_aon_dmac : dma controller
				* 41 : i2c0 aon dma handshake number
				* 0xff : no need to select to dma controller
				*/
				dmas = <&d1_aon_dmac 41 0xff>, <&d1_aon_dmac 42 0xff>;
		};
		d1_aon_i2c1: i2c@71838000 {
				compatible = "snps,designware-i2c";
				clock-frequency = <I2C_BITRATE_STANDARD>;
				clocks = <&d1_clock WIN2030_CLK_AON_I2C1_PCLK>;
				clock-names = "pclk";
				resets = <&d1_reset I2C1_RST_CTRL SW_I2C1_PRSTN>;
				reset-names = "rst";
				#address-cells = <1>;
				#size-cells = <0>;
				reg = <0x0 0x71838000 0x0 0x10000>;
				interrupts = <291>;
				interrupt-parent = <&plic1>;
		};

		d1_npu: eswin-npu@71c00000 {
			compatible = "eswin,npu";
			reg = <0x0 0x71c00000 0x0 0x400000>;
			interrupt-parent = <&plic1>;
			interrupts = <387 16>;
			spram-region = <&npu1_reserved>;
			#size-cells = <2>;
			dma-ranges = <0x1 0x0 0x0 0xc0000000 0x1ff 0x0>;
			iommus = <&smmu1 WIN2030_SID_NPU_DMA>;
			tbus = <WIN2030_TBUID_NPU>;
			dsp-avail-num = <1>;
			spram-size = <0x400000>;
			npu_mbox = <&d1_mbox2>;
			clocks = <&d1_clock WIN2030_CLK_NPU_ACLK>,
					<&d1_clock WIN2030_CLK_NPU_CFG_CLK>,
					<&d1_clock WIN2030_CLK_NPU_CLK>,
					<&d1_clock WIN2030_CLK_NPU_E31_CLK>;
			clock-names = "aclk", "cfg_clk", "core_clk", "e31_core_clk";

			resets = <&d1_reset NPU_RST_CTRL SW_NPU_E31CORE_RSTN>;
			reset-names = "e31_core";

			numa-node-id = <1>;
			firmware-name = "eic7700_die1_e31_fw";
			dma-noncoherent;

			#cooling-cells = <2>;
			dynamic-power-coefficient = <0>; /*TBD*/
		};

		d1_llc_dev: llc@71c00000 {
			compatible = "eswin,llc";
			reg = <0x0 0x71c00000 0x0 0x400000>;
			eswin,syscfg = <&d1_sys_con 0x324>;
			eswin,syscrg_csr = <&d1_sys_crg>;
			clocks = <&d1_clock WIN2030_CLK_NPU_ACLK>,
				 <&d1_clock WIN2030_CLK_NPU_CFG_CLK>,
				 <&d1_clock WIN2030_CLK_NPU_LLC_ACLK>,
				 <&d1_clock WIN2030_CLK_NPU_CLK>,
				 <&d1_clock WIN2030_MUX_U_NPU_CORE_3MUX1_GFREE>,
				 <&d1_clock WIN2030_SPLL2_FOUT2>,
				 <&d1_clock WIN2030_SPLL1_FOUT1>;
			clock-names = "aclk", "cfg_clk", "llc_clk", "core_clk",
					"mux_u_npu_core_3mux1_gfree", "fixed_rate_clk_spll2_fout2",
					"fixed_rate_clk_spll1_fout1";
			resets = <&d1_reset NPU_RST_CTRL SW_NPU_AXI_RSTN>,
				 <&d1_reset NPU_RST_CTRL SW_NPU_CFG_RSTN>,
				 <&d1_reset NPU_RST_CTRL SW_NPU_CORE_RSTN>,
				 <&d1_reset NPU_RST_CTRL SW_NPU_LLC_RSTN>;
			reset-names = "axi", "cfg", "core", "llc";
			numa-node-id = <1>;
			spram-region = <&npu1_reserved>;
		};

		d1_gpu: gpu@71400000 {
			compatible = "img,gpu";
			#address-cells = <2>;
			#size-cells = <2>;
			reg = <0x0 0x71400000 0x0 0xFFFFF>;
			clocks = <&d1_clock WIN2030_CLK_GPU_ACLK>,
					<&d1_clock WIN2030_CLK_GPU_GRAY_CLK>,
					<&d1_clock WIN2030_CLK_GPU_CFG_CLK>;
			clock-names = "aclk", "gray_clk", "cfg_clk";
			resets =<&d1_reset GPU_RST_CTRL SW_GPU_AXI_RSTN>,
					<&d1_reset GPU_RST_CTRL SW_GPU_CFG_RSTN>,
					<&d1_reset GPU_RST_CTRL SW_GPU_GRAY_RSTN>,
					<&d1_reset GPU_RST_CTRL SW_GPU_JONES_RSTN>,
					<&d1_reset GPU_RST_CTRL SW_GPU_SPU_RSTN>;
			reset-names = "axi", "cfg", "gray", "jones","spu";
			interrupt-parent = <&plic1>;
			interrupts = <15>;
			dma-noncoherent;

			#cooling-cells = <2>;
			dynamic-power-coefficient = <0>; /*TBD*/
		};

		d1_sata: sata@0x70420000 {
				compatible = "snps,eswin-ahci";
				reg = <0x0 0x70420000 0x0 0x10000>;
				interrupt-parent = <&plic1>;
				interrupt-names = "intrq", "msi", "pme";
				interrupts = <58>, <59>, <60>;
				ports-implemented = <0x1>;
				resets = <&d1_reset HSPDMA_RST_CTRL SW_HSP_SATA_ARSTN>;
				reset-names = "apb";
				#size-cells = <2>;
				iommus = <&smmu1 WIN2030_SID_SATA>;
				tbus = <WIN2030_TBUID_SATA>;
				dma-ranges = <0x0 0x0 0x0 0xc0000000 0x200 0x0>;
				eswin,hsp_sp_csr = <&d1_hsp_sp_csr 0x1050>;
				eswin,syscrg_csr = <&d1_sys_crg 0x41c>;
				numa-node-id = <1>;
				dma-noncoherent;
		};

		d1_pinctrl: pinctrl@0x71600080 {
			compatible = "eswin,eic7x-pinctrl";
			reg = <0x0 0x71600080 0x0 0x1FFF80>;
			status = "disabled";
			d1_pinctrl_pwm0_default: pwm0-default{
				mux{
					groups = "pwm0_group";
					function = "pwm0_func";
				};
				conf {
					groups = "pwm0_group";
					drive-strength = <5>;
					bias-pull-up = <1>;
					input-enable = <0>;
				};
			};
			d1_pinctrl_pwm1_default: pwm1-default{
				mux{
					groups = "pwm1_group";
					function = "pwm1_func";
				};
			conf {
				groups = "pwm1_group";
				drive-strength = <6>;
				bias-pull-up = <0>;
				input-enable = <1>;
				};
			};
			d1_pinctrl_pwm2_default: pwm2-default{
				mux{
					groups = "pwm2_group";
					function = "pwm2_func";
				};
				conf {
					groups = "pwm2_group";
					drive-strength = <7>;
					bias-pull-down = <0>;
					input-enable = <0>;
				};
			};
		};

		d1_gpio0: gpio@71600000 {
			#address-cells = <1>;
			#size-cells = <0>;
			compatible = "snps,dw-apb-gpio";
			reg = <0x0 0x71600000 0x0 0x80>;

			d1_porta: gpio-port@0 {
				compatible = "snps,dw-apb-gpio-port";
				gpio-controller;
				#gpio-cells = <2>;
				ngpios = <32>;
				reg = <0>;
				interrupt-parent = <&plic1>;
				interrupt-controller;
				#interrupt-cells = <2>;
				interrupts = <303 304 305 306 307 308 309 310 311 312 313 314 315 316 317 318
								319 320 321 322 323 324 325 326 327 328 329 330 331 332 333 334>;
			};

			d1_portb: gpio-port@1 {
				compatible = "snps,dw-apb-gpio-port";
				gpio-controller;
				#gpio-cells = <2>;
				ngpios = <32>;
				reg = <1>;
			};

			d1_portc: gpio-port@2 {
				compatible = "snps,dw-apb-gpio-port";
				gpio-controller;
				#gpio-cells = <2>;
				ngpios = <32>;
				reg = <2>;
			};

			d1_portd: gpio-port@3 {
				compatible = "snps,dw-apb-gpio-port";
				gpio-controller;
				#gpio-cells = <2>;
				ngpios = <16>;
				reg = <3>;
			};
		};

		d1_timer0: timer@0x71840000 {
			compatible = "eswin,eswin-timer";
			#address-cells = <2>;
			#size-cells = <2>;
			reg = <0x0 0x71840000 0x0 0x8000>;
			interrupt-parent = <&plic1>;
			interrupts = <345>;
			clock-names = "pclk","timer_aclk";
			clocks = <&d1_clock WIN2030_CLK_TIMER_PCLK_0>,
					 <&d1_clock WIN2030_CLK_TIMER_CLK_0>;
			resets = <&d1_reset TIMER0_RST_CTRL SW_TIMER0_RSTN_0>,
				<&d1_reset TIMER0_RST_CTRL SW_TIMER0_RSTN_1>,
				<&d1_reset TIMER0_RST_CTRL SW_TIMER0_RSTN_2>,
				<&d1_reset TIMER0_RST_CTRL SW_TIMER0_RSTN_3>,
				<&d1_reset TIMER0_RST_CTRL SW_TIMER0_RSTN_4>,
				<&d1_reset TIMER0_RST_CTRL SW_TIMER0_RSTN_5>,
				<&d1_reset TIMER0_RST_CTRL SW_TIMER0_RSTN_6>,
				<&d1_reset TIMER0_RST_CTRL SW_TIMER0_RSTN_7>,
				<&d1_reset TIMER0_RST_CTRL SW_TIMER0_PRSTN>;
			reset-names = "trst0","trst1","trst2","trst3","trst4","trst5","trst6","trst7","prst";
		};

		d1_timer1: timer@0x71848000 {
			compatible = "eswin,eswin-timer";
			#address-cells = <2>;
			#size-cells = <2>;
			reg = <0x0 0x71848000 0x0 0x8000>;
			interrupt-parent = <&plic1>;
			interrupts = <346>;
			clock-names = "pclk","timer_aclk";
			clocks = <&d1_clock WIN2030_CLK_TIMER_PCLK_1>,
					 <&d1_clock WIN2030_CLK_TIMER_CLK_1>;
			resets = <&d1_reset TIMER1_RST_CTRL SW_TIMER1_RSTN_0>,
				<&d1_reset TIMER1_RST_CTRL SW_TIMER1_RSTN_1>,
				<&d1_reset TIMER1_RST_CTRL SW_TIMER1_RSTN_2>,
				<&d1_reset TIMER1_RST_CTRL SW_TIMER1_RSTN_3>,
				<&d1_reset TIMER1_RST_CTRL SW_TIMER1_RSTN_4>,
				<&d1_reset TIMER1_RST_CTRL SW_TIMER1_RSTN_5>,
				<&d1_reset TIMER1_RST_CTRL SW_TIMER1_RSTN_6>,
				<&d1_reset TIMER1_RST_CTRL SW_TIMER1_RSTN_7>,
				<&d1_reset TIMER1_RST_CTRL SW_TIMER1_PRSTN>;
			reset-names = "trst0","trst1","trst2","trst3","trst4","trst5","trst6","trst7","prst";
		};


		d1_timer2: timer@0x71850000 {
			compatible = "eswin,eswin-timer";
			#address-cells = <2>;
			#size-cells = <2>;
			reg = <0x0 0x71850000 0x0 0x8000>;
			interrupt-parent = <&plic1>;
			interrupts = <347>;
			clock-names = "pclk","timer_aclk";
			clocks = <&d1_clock WIN2030_CLK_TIMER_PCLK_2>,
					 <&d1_clock WIN2030_CLK_TIMER_CLK_2>;
			resets = <&d1_reset TIMER2_RST_CTRL SW_TIMER2_RSTN_0>,
				<&d1_reset TIMER2_RST_CTRL SW_TIMER2_RSTN_1>,
				<&d1_reset TIMER2_RST_CTRL SW_TIMER2_RSTN_2>,
				<&d1_reset TIMER2_RST_CTRL SW_TIMER2_RSTN_3>,
				<&d1_reset TIMER2_RST_CTRL SW_TIMER2_RSTN_4>,
				<&d1_reset TIMER2_RST_CTRL SW_TIMER2_RSTN_5>,
				<&d1_reset TIMER2_RST_CTRL SW_TIMER2_RSTN_6>,
				<&d1_reset TIMER2_RST_CTRL SW_TIMER2_RSTN_7>,
				<&d1_reset TIMER2_RST_CTRL SW_TIMER2_PRSTN>;
			reset-names = "trst0","trst1","trst2","trst3","trst4","trst5","trst6","trst7","prst";
		};

		d1_timer3: timer@0x71858000 {
			compatible = "eswin,eswin-timer";
			#address-cells = <2>;
			#size-cells = <2>;
			reg = <0x0 0x71858000 0x0 0x8000>;
			interrupt-parent = <&plic1>;
			interrupts = <348>;
			clock-names = "pclk","timer_aclk","timer3_clk8";
			clocks = <&d1_clock WIN2030_CLK_TIMER_PCLK_3>,
					 <&d1_clock WIN2030_CLK_TIMER_CLK_3>,
					 <&d1_clock WIN2030_CLK_TIMER3_CLK8>;
			resets = <&d1_reset TIMER3_RST_CTRL SW_TIMER3_RSTN_0>,
				<&d1_reset TIMER3_RST_CTRL SW_TIMER3_RSTN_1>,
				<&d1_reset TIMER3_RST_CTRL SW_TIMER3_RSTN_2>,
				<&d1_reset TIMER3_RST_CTRL SW_TIMER3_RSTN_3>,
				<&d1_reset TIMER3_RST_CTRL SW_TIMER3_RSTN_4>,
				<&d1_reset TIMER3_RST_CTRL SW_TIMER3_RSTN_5>,
				<&d1_reset TIMER3_RST_CTRL SW_TIMER3_RSTN_6>,
				<&d1_reset TIMER3_RST_CTRL SW_TIMER3_RSTN_7>,
				<&d1_reset TIMER3_RST_CTRL SW_TIMER3_PRSTN>;
			reset-names = "trst0","trst1","trst2","trst3","trst4","trst5","trst6","trst7","prst";
		};

		d1_pwm0: pwm@0x70818000 {
			compatible = "eswin,pwm-eswin";
			reg = <0x0 0x70818000 0x0 0x4000>;
			clock-names = "pwm","pclk";
			clocks = <&d1_clock WIN2030_CLK_LSP_TIMER_PCLK>;
			clock-frequency = <200000000>;
			resets = <&d1_reset TIMER_RST_CTRL SW_TIMER_RST_N>;
			reset-names = "pwmrst";
			#pwm-cells = <2>;
			pinctrl-names = "default";
			pinctrl-0 = <&d1_pinctrl_pwm0_default &d1_pinctrl_pwm1_default &d1_pinctrl_pwm2_default>;
			status = "disabled";
		};

		d1_i2s0: i2s0@70200000 {
			compatible = "snps,i2s";
			clocks = <&d1_clock WIN2030_CLK_VO_I2S_MCLK>;
			clock-names = "mclk";
			#address-cells = <1>;
			#size-cells = <0>;
			#sound-dai-cells = <0x00000000>;
			reg = <0x0 0x70200000 0x0 0x10000>;
			dma-names = "rx", "tx";
			dmas = <&d1_aon_dmac 4 0>, <&d1_aon_dmac 5 0>;
			vo_mclk_sel,syscrg = <&d1_sys_crg 0x1bc>;
			resets = <&d1_reset VO_I2SRST_CTRL SW_VO_I2S_RSTN>,
				<&d1_reset VO_I2SRST_CTRL SW_VO_I2S_PRSTN>,
				<&d1_reset VO_PHYRST_CTRL SW_VO_PRSTN>;
			reset-names = "i2srst", "i2sprst", "voprst";
			dma-noncoherent;
		};

		d1_i2s1: i2s1@70210000 {
			compatible = "snps,i2s";
			clocks = <&d1_clock WIN2030_CLK_VO_I2S_MCLK>;
			clock-names = "mclk";
			#address-cells = <1>;
			#size-cells = <0>;
			#sound-dai-cells = <0x00000000>;
			reg = <0x0 0x70210000 0x0 0x10000>;
			dma-names = "rx", "tx";
			dmas = <&d1_aon_dmac 2 1>, <&d1_aon_dmac 3 1>;
			vo_mclk_sel,syscrg = <&d1_sys_crg 0x1bc>;
			resets = <&d1_reset VO_I2SRST_CTRL SW_VO_I2S_RSTN>,
				<&d1_reset VO_I2SRST_CTRL SW_VO_I2S_PRSTN>,
				<&d1_reset VO_PHYRST_CTRL SW_VO_PRSTN>;
			reset-names = "i2srst", "i2sprst", "voprst";
			dma-noncoherent;
		};

		d1_i2s2: i2s@70220000 {
			compatible = "snps,i2s";
			clocks = <&d1_clock WIN2030_CLK_VO_I2S_MCLK>;
			clock-names = "mclk";
			#address-cells = <1>;
			#size-cells = <0>;
			#sound-dai-cells = <0x00000000>;
			reg = <0x0 0x70220000 0x0 0x10000>;
			dma-names = "rx", "tx";
			dmas = <&d1_aon_dmac 0 2>, <&d1_aon_dmac 1 2>;
			vo_mclk_sel,syscrg = <&d1_sys_crg 0x1bc>;
			resets = <&d1_reset VO_I2SRST_CTRL SW_VO_I2S_RSTN>,
				<&d1_reset VO_I2SRST_CTRL SW_VO_I2S_PRSTN>,
				<&d1_reset VO_PHYRST_CTRL SW_VO_PRSTN>;
			reset-names = "i2srst", "i2sprst", "voprst";
			dma-noncoherent;
		};

		d1_graphcard0: graphcard4 {
			compatible = "audio-graph-card";
		};

		d1_graphcard1: graphcard5 {
			compatible = "audio-graph-card";
		};

		d1_graphcard2: graphcard6 {
			compatible = "audio-graph-card";
		};

		d1_dsp_subsys:dsp_subsys@72280400 {
			#address-cells = <2>;
			#size-cells = <2>;
			reg = <0x0 0x72280400 0x0 0x10000>,
				<0x0 0x71810000 0x0 0x8000>;
			ranges;
			dma-ranges = <0x0 0x30000000 0x0 0xc0000000 0x0 0xce000000>;
			compatible = "es-dsp-subsys", "simple-bus";
			clocks = <&d1_clock WIN2030_CLK_DSPT_CFG_CLK>,  <&d1_clock WIN2030_CLK_DSPT_ACLK>;
			clock-names = "cfg_clk", "aclk";
			resets = <&d1_reset DSP_RST_CTRL SW_DSP_AXI_RSTN>,
				<&d1_reset DSP_RST_CTRL SW_DSP_CFG_RSTN>,
				<&d1_reset DSP_RST_CTRL SW_DSP_DIV4_RSTN>,
				<&d1_reset DSP_RST_CTRL SW_DSP_DIV_RSTN_0>,
				<&d1_reset DSP_RST_CTRL SW_DSP_DIV_RSTN_1>,
				<&d1_reset DSP_RST_CTRL SW_DSP_DIV_RSTN_2>,
				<&d1_reset DSP_RST_CTRL SW_DSP_DIV_RSTN_3>;
			reset-names = "axi", "cfg", "div4", "div_0", "div_1", "div_2","div_3";
			d1_dsp0:es_dsp@0 {
				#address-cells = <1>;
				#size-cells = <1>;
				compatible = "eswin-dsp", "cdns,xrp-hw-eswin";
				ranges = <0x28000000 0 0x7b000000 0x8000
					0x28100000 0 0x7b100000 0x20000
					0x28120000 0 0x7b120000 0x20000>;
				clocks = <&d1_clock WIN2030_CLK_DSP_ACLK_0>;
				clock-names = "aclk";
				dsp_mbox = <&d1_mbox4>;
				device-irq = <11
					(ESWIN_MAILBOX_DSP_0_TO_U84_REG_BASE + 0x20000000)
					ESWIN_MAILBOX_WR_LOCK_BIT_DSP_0
					(ESWIN_MAILBOX_U84_TO_DSP_0_REG_BASE + 0x20000000)
					ESWIN_MAIBOX_U84_IRQ_BIT
					(ESWIN_MAILBOX_U84_TO_NPU_0_REG_BASE + 0x20000000)>;
				device-uart = <0x70910000>;
				device-irq-mode = <1>;
				host-irq-mode = <1>;
				firmware-name = "eic7700_dsp_fw";
				process-id = <0>;
				iommus = <&smmu1 WIN2030_SID_DSP_0>;
				tbus = <WIN2030_TBUID_DSP0>;
				dma-noncoherent;
				numa-node-id = <1>;
				aux-e31-dtim = <0x7a110000>;
				dsp@0 {
				};
			};
			d1_dsp1:es_dsp@1 {
				#address-cells = <1>;
				#size-cells = <1>;
				compatible = "eswin-dsp", "cdns,xrp-hw-eswin";
				ranges = <0x28000000 0 0x7b008000 0x8000
					0x28100000 0 0x7b140000 0x20000
					0x28120000 0 0x7b160000 0x20000>;
				clocks = <&d1_clock WIN2030_CLK_DSP_ACLK_1>;
				clock-names = "aclk";
				dsp_mbox = <&d1_mbox5>;
				device-irq = <13
					(ESWIN_MAILBOX_DSP_1_TO_U84_REG_BASE + 0x20000000)
					ESWIN_MAILBOX_WR_LOCK_BIT_DSP_1
					(ESWIN_MAILBOX_U84_TO_DSP_1_REG_BASE + 0x20000000)
					ESWIN_MAIBOX_U84_IRQ_BIT
					(ESWIN_MAILBOX_U84_TO_NPU_0_REG_BASE + 0x20000000)>;
				device-uart = <0x70910000>;
				device-irq-mode = <1>;
				host-irq-mode = <1>;
				firmware-name = "eic7700_dsp_fw";
				process-id = <1>;
				iommus = <&smmu1 WIN2030_SID_DSP_1>;
				tbus = <WIN2030_TBUID_DSP1>;
				dma-noncoherent;
				numa-node-id = <1>;
				aux-e31-dtim = <0x7a110000>;
				dsp@0 {
				};
			};
			d1_dsp2:es_dsp@2 {
				#address-cells = <1>;
				#size-cells = <1>;
				compatible = "eswin-dsp", "cdns,xrp-hw-eswin";
				ranges = <0x28000000 0 0x7b010000 0x8000
					0x28100000 0 0x7b180000 0x20000
					0x28120000 0 0x7b1a0000 0x20000>;
				clocks = <&d1_clock WIN2030_CLK_DSP_ACLK_2>;
				clock-names = "aclk";
				dsp_mbox = <&d1_mbox6>;
				device-irq = <15
					(ESWIN_MAILBOX_DSP_2_TO_U84_REG_BASE + 0x20000000)
					ESWIN_MAILBOX_WR_LOCK_BIT_DSP_2
					(ESWIN_MAILBOX_U84_TO_DSP_2_REG_BASE + 0x20000000)
					ESWIN_MAIBOX_U84_IRQ_BIT
					(ESWIN_MAILBOX_U84_TO_NPU_0_REG_BASE + 0x20000000)>;
				device-uart = <0x70910000>;
				device-irq-mode = <1>;
				host-irq-mode = <1>;
				firmware-name = "eic7700_dsp_fw";
				process-id = <2>;
				iommus = <&smmu1 WIN2030_SID_DSP_2>;
				tbus = <WIN2030_TBUID_DSP2>;
				dma-noncoherent;
				numa-node-id = <1>;
				aux-e31-dtim = <0x7a110000>;
				dsp@0 {
				};
			};
			d1_dsp3:es_dsp@3 {
				#address-cells = <1>;
				#size-cells = <1>;
				compatible = "eswin-dsp", "cdns,xrp-hw-eswin";
				ranges = <0x28000000 0 0x7b018000 0x8000
					0x28100000 0 0x7b1c0000 0x20000
					0x28120000 0 0x7b1e0000 0x20000>;
				clocks = <&d1_clock WIN2030_CLK_DSP_ACLK_3>;
				clock-names = "aclk";
				dsp_mbox = <&d1_mbox7>;
				device-irq = <17
					(ESWIN_MAILBOX_DSP_3_TO_U84_REG_BASE + 0x20000000)
					ESWIN_MAILBOX_WR_LOCK_BIT_DSP_3
					(ESWIN_MAILBOX_U84_TO_DSP_3_REG_BASE + 0x20000000)
					ESWIN_MAIBOX_U84_IRQ_BIT
					(ESWIN_MAILBOX_U84_TO_NPU_0_REG_BASE + 0x20000000)>;
				device-uart = <0x70910000>;
				device-irq-mode = <1>;
				host-irq-mode = <1>;
				firmware-name = "eic7700_dsp_fw";
				process-id = <3>;
				iommus = <&smmu1 WIN2030_SID_DSP_3>;
				tbus = <WIN2030_TBUID_DSP3>;
				dma-noncoherent;
				numa-node-id = <1>;
				aux-e31-dtim = <0x7a110000>;
				dsp@0 {
				};
			};
		};
		d1_rtc: rtc@71818000 {
			compatible = "eswin,win2030-rtc";
			reg = <0x0 0x71818000 0x0 0x400>;
			eswin,syscfg = <&d1_sys_con 0x3c0>;
			interrupt-parent = <&plic1>;
			interrupts = <292>;
			clocks = <&d1_clock WIN2030_CLK_CLK_RTC>;
			clock-names = "rtcclk";
			clock-frequency = <15625>;
			resets = <&d1_reset RTC_RST_CTRL SW_RTC_RSTN>;
			reset-names = "rtcrst";
			status = "disabled";
		};

		d1_pcie: pcie@0x74000000 {
			compatible = "eswin,win2030-pcie";
			clocks = <&d1_clock WIN2030_CLK_PCIET_ACLK>,
				 <&d1_clock WIN2030_CLK_PCIET_CFG_CLK>,
				 <&d1_clock WIN2030_CLK_PCIET_CR_CLK>,
				 <&d1_clock WIN2030_CLK_PCIET_AUX_CLK>;
			clock-names = "pcie_aclk", "pcie_cfg_clk", "pcie_cr_clk", "pcie_aux_clk";

			reset-names = "pcie_cfg", "pcie_powerup", "pcie_pwren";
			resets = <&d1_reset PCIE_RST_CTRL SW_PCIE_CFG_RSTN>,
				 <&d1_reset PCIE_RST_CTRL SW_PCIE_POWERUP_RSTN>,
				 <&d1_reset PCIE_RST_CTRL SW_PCIE_PERST_N>;

			#address-cells = <3>;
			#size-cells = <2>;
			#interrupt-cells = <1>;
			reg = <0x0 0x74000000 0x0 0x4000000>,	/* IP registers */
				  <0x0 0x60000000 0x0 0x800000>,	/* Configuration space */
				  <0x0 0x70000000 0x0 0x100000>;
			reg-names = "dbi", "config", "mgmt";
			device_type = "pci";
			/* dma-coherent; */
			bus-range = <0x0 0xff>;

			ranges = <0x81000000  0x0 0x60800000  0x0 0x60800000 0x0 0x800000>,	  /* I/O */
				 <0x82000000  0x0 0x61000000  0x0 0x61000000 0x0 0xf000000>,	/* mem */
				 <0xc3000000 0xa0 0x00000000 0xa0 0x00000000 0x2 0x00000000>;  /* mem prefetchable */

			num-lanes = <0x4>;
			/**********************************
			  	msi_ctrl_io[0~31] : 188~219
			  	msi_ctrl_int : 220
			**********************************/
			interrupts = <220>, <179>, <180>, <181>, <182>, <183>, <184>, <185>, <186>;
			interrupt-names = "msi", "inta", "intb", "intc", "intd";
			interrupt-parent = <&plic1>;
			interrupt-map-mask = <0x0 0x0 0x0 0x7>;
			interrupt-map = <0x0 0x0 0x0 0x1 &plic1 179>,
							<0x0 0x0 0x0 0x2 &plic1 180>,
							<0x0 0x0 0x0 0x3 &plic1 181>,
							<0x0 0x0 0x0 0x4 &plic1 182>;
			iommus = <&smmu1 0xfe0000>;
			iommu-map = <0x0 &smmu1 0xff0000 0xffffff>;
			tbus = <WIN2030_TBUID_PCIE>;
			status = "disabled";
			numa-node-id = <1>;
			dma-noncoherent;
		};

		d1_gmac0: ethernet@70400000 {
			compatible = "eswin,win2030-qos-eth";
			reg = <0x0 0x70400000 0x0 0x10000>;
			interrupt-parent = <&plic1>;
			interrupt-names = "macirq";
			interrupts = <61>;
			phy-mode = "rgmii";
			numa-node-id = <1>;
			id = <2>;
			status = "disabled";
			clocks = <&d1_clock WIN2030_CLK_HSP_ETH_APP_CLK>,
					 <&d1_clock WIN2030_CLK_HSP_ETH_CSR_CLK>,
					 <&d1_clock WIN2030_CLK_HSP_ETH0_CORE_CLK>;
			clock-names = "app", "stmmaceth","tx";
			resets = <&d1_reset HSPDMA_RST_CTRL SW_HSP_ETH0_ARSTN>;
			reset-names = "ethrst";
			iommus = <&smmu1 WIN2030_SID_ETH0>;
			tbus = <WIN2030_TBUID_ETH>;
			dma-noncoherent;
			eswin,hsp_sp_csr = <&d1_hsp_sp_csr 0x1030 0x100 0x108>;
			eswin,syscrg_csr = <&d1_sys_crg 0x148 0x14c>;
			snps,axi-config = <&d1_stmmac_axi_setup>;
			d1_stmmac_axi_setup: stmmac-axi-config {
				snps,blen = <0 0 0 0 16 8 4>;
				snps,rd_osr_lmt = <2>;
				snps,wr_osr_lmt = <2>;
				snps,lpi_en = <0>;
			};
		};

		d1_gmac1: ethernet@70410000 {
			compatible = "eswin,win2030-qos-eth";
			reg = <0x0 0x70410000 0x0 0x10000>;
			interrupt-parent = <&plic1>;
			interrupt-names = "macirq";
			interrupts = <70>;
			phy-mode = "rgmii";
			numa-node-id = <1>;
			id = <3>;
			status = "disabled";
			clocks = <&d1_clock WIN2030_CLK_HSP_ETH_APP_CLK>,
					 <&d1_clock WIN2030_CLK_HSP_ETH_CSR_CLK>,
					 <&d1_clock WIN2030_CLK_HSP_ETH1_CORE_CLK>;
			clock-names = "app", "stmmaceth","tx";
			resets = <&d1_reset HSPDMA_RST_CTRL SW_HSP_ETH1_ARSTN>;
			reset-names = "ethrst";
			iommus = <&smmu1 WIN2030_SID_ETH1>;
			tbus = <WIN2030_TBUID_ETH>;
			dma-noncoherent;
			eswin,hsp_sp_csr = <&d1_hsp_sp_csr 0x1034 0x200 0x208>;
			eswin,syscrg_csr = <&d1_sys_crg 0x148 0x14c>;
			snps,axi-config = <&d1_stmmac_axi_setup_gmac1>;
			d1_stmmac_axi_setup_gmac1: stmmac-axi-config {
				snps,blen = <0 0 0 0 16 8 4>;
				snps,rd_osr_lmt = <2>;
				snps,wr_osr_lmt = <2>;
				snps,lpi_en = <0>;
			};
		};

		d1_sdhci_emmc: mmc@70450000 {
			compatible = "eswin,emmc-sdhci-5.1";
			reg = <0x0 0x70450000 0x0 0x10000>;
			interrupt-parent = <&plic1>;
			interrupts = <79>;
			assigned-clocks = <&d1_clock WIN2030_CLK_HSP_MSHC0_CORE_CLK>;
			assigned-clock-rates = <200000000>;
			clocks = <&d1_clock WIN2030_CLK_HSP_MSHC0_CORE_CLK>, <&d1_clock WIN2030_CLK_HSP_CFG_CLK>;
			clock-names = "clk_xin", "clk_ahb";
			clock-output-names = "d1_emmc_cardclock";
			#clock-cells = <0>;

			resets = <&d1_reset HSPDMA_RST_CTRL SW_MSHC0_TXRX_RSTN>,
				<&d1_reset HSPDMA_RST_CTRL SW_MSHC0_PHY_RSTN>,
				<&d1_reset HSPDMA_RST_CTRL SW_HSP_EMMC_PRSTN>,
				<&d1_reset HSPDMA_RST_CTRL SW_HSP_EMMC_ARSTN>;
			reset-names = "txrx_rst", "phy_rst", "prstn", "arstn";

			disable-cqe-dcmd;
			bus-width = <8>;
			non-removable;
			/* mmc-ddr-1_8v; */
			mmc-hs400-1_8v;
			max-frequency = <200000000>;
			/* sdhci-caps-mask =  <0x0 0x3200000>; */
			/* smmu */
			#size-cells = <2>;
			iommus = <&smmu1 WIN2030_SID_EMMC0>;
			tbus = <WIN2030_TBUID_EMMC>;
			dma-ranges = <0x0 0x00000000 0x0 0xc0000000 0x1 0x0>;
			eswin,hsp_sp_csr = <&d1_hsp_sp_csr 0x1038 0x508 0x50c>;
			eswin,syscrg_csr = <&d1_sys_crg 0x160 0x148 0x14c>;
			status = "disabled";
			numa-node-id = <1>;
			dma-noncoherent;
		};

		d1_sdio0: mmc@0x70460000{
			compatible = "eswin,sdhci-sdio";
			reg = <0x0 0x70460000 0x0 0x10000>;
			interrupt-parent = <&plic1>;
			interrupts = <81>;
			clocks =<&d1_clock WIN2030_CLK_HSP_MSHC1_CORE_CLK>,
				<&d1_clock WIN2030_CLK_HSP_CFG_CLK>,
				<&d1_clock WIN2030_SPLL2_FOUT3>,
				<&d1_clock WIN2030_MUX_U_MSHCORE_ROOT_3MUX1_1>;
			clock-names ="clk_xin","clk_ahb","clk_spll2_fout3","clk_mux1_1";
			clock-output-names = "sdio_cardclock";
			#clock-cells = <0>;
			resets = <&d1_reset HSPDMA_RST_CTRL SW_MSHC1_TXRX_RSTN>,
				<&d1_reset HSPDMA_RST_CTRL SW_MSHC1_PHY_RSTN>,
				<&d1_reset HSPDMA_RST_CTRL SW_HSP_SD0_PRSTN>,
				<&d1_reset HSPDMA_RST_CTRL SW_HSP_SD0_ARSTN>;
			reset-names = "txrx_rst","phy_rst","prstn","arstn";

			clock-frequency = <208000000>;
			max-frequency = <208000000>;
			#address-cells = <1>;
			#size-cells = <0>;
			dma-ranges = <0x0 0x20000000 0x0 0xc0000000 0x0 0x40000000>;
			iommus = <&smmu1 WIN2030_SID_SD0>;
			tbus = <WIN2030_TBUID_SD>;
			eswin,hsp_sp_csr = <&d1_hsp_sp_csr 0x103c 0x608 0x60c>;
			eswin,syscrg_csr = <&d1_sys_crg 0x164 0x148 0x14c>;
			bus-width = <4>;
			sdio-id = <0>;
			numa-node-id = <1>;
			status = "disabled";
			dma-noncoherent;
		};

		d1_sdio1: mmc@0x70470000{
			compatible = "eswin,sdhci-sdio";
			reg = <0x0 0x70470000 0x0 0x10000>;
			interrupt-parent = <&plic1>;
			interrupts = <83>;
			clocks =<&d1_clock WIN2030_CLK_HSP_MSHC2_CORE_CLK>,
				<&d1_clock WIN2030_CLK_HSP_CFG_CLK>,
				<&d1_clock WIN2030_SPLL2_FOUT3>,
				<&d1_clock WIN2030_MUX_U_MSHCORE_ROOT_3MUX1_1>;
			clock-names ="clk_xin","clk_ahb","clk_spll2_fout3","clk_mux1_1";
			clock-output-names = "sdio_cardclock";
			#clock-cells = <0>;
			resets = <&d1_reset HSPDMA_RST_CTRL SW_MSHC2_TXRX_RSTN>,
				<&d1_reset HSPDMA_RST_CTRL SW_MSHC2_PHY_RSTN>,
				<&d1_reset HSPDMA_RST_CTRL SW_HSP_SD1_PRSTN>,
				<&d1_reset HSPDMA_RST_CTRL SW_HSP_SD1_ARSTN>;
			reset-names = "txrx_rst","phy_rst","prstn","arstn";

			clock-frequency = <208000000>;
			max-frequency = <208000000>;
			#address-cells = <1>;
			#size-cells = <0>;
			dma-ranges = <0x0 0x20000000 0x0 0xc0000000 0x0 0x40000000>;
			iommus = <&smmu1 WIN2030_SID_SD1>;
			tbus = <WIN2030_TBUID_SD>;
			eswin,hsp_sp_csr = <&d1_hsp_sp_csr 0x1040 0x708 0x70c>;
			eswin,syscrg_csr = <&d1_sys_crg 0x168 0x148 0x14c>;
			bus-width = <4>;
			sdio-id = <1>;
			numa-node-id = <1>;
			status = "disabled";
			dma-noncoherent;
		};

		d1_ssi0: spi1@70810000 {
			compatible = "snps,eic770x-spi";
			#address-cells = <1>;
			#size-cells = <0>;
			reg = <0x0 0x70810000 0x0 0x4000>;
			spi-max-frequency = <4800000>;
			clocks = <&d1_clock WIN2030_CLK_LSP_SSI0_PCLK>;
			clock-names = "clk";
			interrupt-parent = <&plic1>;
			interrupts = <91>;
			resets = <&d1_reset SSI_RST_CTRL SW_SSI_RST_N_0>;
			reset-names = "spi";
			numa-node-id = <1>;
			status = "disabled";
			dma-noncoherent;
		};

		d1_ssi1: spi@70814000 {
			compatible = "snps,eic770x-spi";
			#address-cells = <1>;
			#size-cells = <0>;
			reg = <0x0 0x70814000 0x0 0x4000>;
			spi-max-frequency = <4800000>;
			clocks = <&d1_clock WIN2030_CLK_LSP_SSI1_PCLK>;
			clock-names = "clk";
			interrupt-parent = <&plic1>;
			interrupts = <92>;
			resets = <&d1_reset SSI_RST_CTRL SW_SSI_RST_N_1>;
			reset-names = "spi";
			numa-node-id = <1>;
			status = "disabled";
			dma-noncoherent;
		};

		d1_bootspi: spi@71800000 {
			compatible = "eswin,bootspi";
			reg = <0x0 0x71800000 0x0 0x8000>,
				<0x0 0x71828000 0x0 0x8000>,
				<0x0 0x7c000000 0x0 0x8000>;
			#address-cells = <1>;
			#size-cells = <0>;
			clocks = <&d1_clock WIN2030_CLK_CLK_BOOTSPI_CFG>,
					<&d1_clock WIN2030_CLK_CLK_BOOTSPI>;
			clock-names = "cfg_clk", "clk";
			resets = <&d1_reset BOOTSPI_RST_CTRL SW_BOOTSPI_RSTN>;
			reset-names = "rst";
			spi-max-frequency = <4800000>;
			reg-io-width = <4>;
			status = "disabled";
		};

		d1_video_output: display-subsystem@1 {
			compatible = "eswin,display-subsystem";
			ports = <&d1_dc_out>;
			numa-node-id = <1>;
			dma-noncoherent;
		};

		d1_dc: display_control@702c0000 {
			compatible = "eswin,dc";
			reg = <0x0 0x702c0000 0x0 0x100>, <0x0 0x702c0180 0x0 0x700>, <0x0 0x702c1400 0x0 0x1400>;
			interrupt-parent = <&plic1>;
			interrupts = <238>;

			clocks = <&d1_clock WIN2030_CLK_VO_CFG_CLK>,
					 <&d1_clock WIN2030_CLK_VO_PIXEL_CLK>,
					 <&d1_clock WIN2030_CLK_VO_ACLK>,
					 <&d1_clock WIN2030_SPLL0_FOUT1>,
					 <&d1_clock WIN2030_MUX_U_VO_ACLK_ROOT_2MUX1_GFREE>;
			clock-names = "cfg_clk", "pix_clk", "axi_clk", "spll0_fout1", "vo_mux";
			resets = <&d1_reset VO_RST_CTRL SW_VO_AXI_RSTN>,
					 <&d1_reset VO_RST_CTRL SW_VO_CFG_RSTN>,
					 <&d1_reset VO_RST_CTRL SW_VO_DC_RSTN>,
					 <&d1_reset VO_RST_CTRL SW_VO_DC_PRSTN>;
			reset-names = "vo_arst", "vo_prst", "dc_arst", "dc_prst";
			dma-noncoherent;
			numa-node-id = <1>;

			d1_dc_out: port {
				#address-cells = <1>;
				#size-cells = <0>;

				d1_dc_out_dsi: endpoint@0 {
					reg = <0>;
					remote-endpoint = <&d1_dsi_input>;
				};

				d1_dc_out_dpi1: endpoint@1 {
					reg = <1>;
					remote-endpoint = <&d1_vd_input>;
				};

				d1_dc_out_hdmi: endpoint@2 {
					reg = <2>;
					remote-endpoint = <&d1_hdmi_in_dc>;
				};
			};
		};

		d1_virtual_display: es_wb@1 {
			compatible = "eswin,virtual_display";
			bpp = /bits/ 8 <8>;
			numa-node-id = <1>;

			port {
				d1_vd_input: endpoint {
					remote-endpoint = <&d1_dc_out_dpi1>;
				};
			};
		};

		d1_dsi_output: dsi-output@1 {
			compatible = "eswin,dsi-encoder";
			numa-node-id = <1>;
			status = "disabled";
		};

		d1_dsi_controller: mipi_dsi@70270000 {
			#address-cells = <1>;
			#size-cells = <0>;
			compatible = "eswin,dsi";
			reg = <0x0 0x70270000 0x0 0x10000>;
			clocks = <&d1_clock WIN2030_CLK_CLK_MIPI_TXESC>;
			clock-names = "pclk";
			resets = <&d1_reset VO_PHYRST_CTRL SW_VO_MIPI_PRSTN>;
			reset-names ="phyrstn";
			numa-node-id = <1>;

			/*
			phys = <&dphy>;
			phy-names = "dphy";
			*/

			ports {
				#address-cells = <1>;
				#size-cells = <0>;

				port@0 {
					#address-cells = <1>;
					#size-cells = <0>;
					reg = <0>;

					d1_dsi_input: endpoint {
						remote-endpoint = <&d1_dc_out_dsi>;
					};
				};

				port@1 {
					#address-cells = <1>;
					#size-cells = <0>;
					reg = <1>;

					d1_mipi_dsi_out: endpoint {
						remote-endpoint = <&d1_panel_in>;
					};
				};
			};

			d1_dsi_panel:dsi_panel@1 {
				compatible = "eswin,generic-panel";
				reg = <0>;
				dsi,format = <0>; //RGB888:0, RGB666:1, RGB565:3
				dsi,lanes = <4>;
				port {
					d1_panel_in: endpoint {
						remote-endpoint = <&d1_mipi_dsi_out>;
					};
				};
			};
		};

		d1_dc_test: dctest@702c0000 {
			compatible = "eswin,dc";
			reg = <0x0 0x702c0000 0x0 0x10000>;
			interrupt-parent = <&plic1>;
			interrupts = <238>;
		};

		d1_dw_hdmi: hdmi@702a0000 {
			compatible = "eswin,eswin-dw-hdmi";
			reg = <0x0 0x702a0000 0x0 0x20000>;
			pinctrl-names = "default";
			//pinctrl-0 = <&hdmi_i2c_xfer>;
			interrupt-parent = <&plic1>;
			interrupts = <274>;
			clocks = <&d1_clock WIN2030_CLK_VO_CFG_CLK>, <&d1_clock WIN2030_CLK_VO_CEC_CLK>,
					 <&d1_clock WIN2030_CLK_VO_CR_CLK>;
			clock-names = "iahb", "cec", "isfr";
			//power-domains = <&power WIN2030_PD_HDCP>;
			reg-io-width = <4>;
			ddc-i2c-scl-high-time-ns = <4708>;
			ddc-i2c-scl-low-time-ns = <4916>;
			#sound-dai-cells = <0>;
			resets = <&d1_reset VO_PHYRST_CTRL SW_VO_HDMI_PRSTN>,
					 <&d1_reset VO_PHYRST_CTRL SW_HDMI_PHYCTRL_RSTN>,
					 <&d1_reset VO_PHYRST_CTRL SW_VO_HDMI_RSTN>;
			reset-names = "prstn", "phyrstn", "rstn";
			numa-node-id = <1>;

			ports {
				port@0 {
					#address-cells = <1>;
					#size-cells = <0>;
					d1_hdmi_in_dc: endpoint@0 {
						reg = <0>;
						remote-endpoint = <&d1_dc_out_hdmi>;
					};
				};
			};
		};

		d1_dw_hdmi_hdcp2: hdmi-hdcp2@70290000 {
			compatible = "eswin,dw-hdmi-hdcp2";
			reg = <0x0 0x70290000 0x0 0x10000>;
			interrupt-parent = <&plic1>;
			interrupts = <275>;
			clocks = <&d1_clock WIN2030_CLK_VO_ACLK>,
				 <&d1_clock WIN2030_CLK_VO_HDMI_IESMCLK>;
			clock-names ="aclk", "iesmclk";
			dma-noncoherent;
			numa-node-id = <1>;
		};

		d1_wdt0: watchdog@0x70800000 {
			compatible = "snps,dw-wdt";
			reg = <0x0 0x70800000 0x0 0x4000>;
			clocks =<&d1_clock WIN2030_CLK_LSP_WDT0_PCLK>;
			clock-names = "pclk";
			resets = <&d1_reset WDT_RST_CTRL SW_WDT_RST_N_0>;
			reset-names = "rst";
			interrupts = <87>;
			interrupt-parent = <&plic1>;
			status = "disabled";
		};

		d1_wdt1: watchdog@0x70804000 {
			compatible = "snps,dw-wdt";
			reg = <0x0 0x70804000 0x0 0x4000>;
			clocks =<&d1_clock WIN2030_CLK_LSP_WDT1_PCLK>;
			clock-names = "pclk";
			resets = <&d1_reset WDT_RST_CTRL SW_WDT_RST_N_1>;
			reset-names = "rst";
			interrupts = <88>;
			interrupt-parent = <&plic1>;
			status = "disabled";
		};

		d1_wdt2: watchdog@0x70808000 {
			compatible = "snps,dw-wdt";
			reg = <0x0 0x70808000 0x0 0x4000>;
			clocks =<&d1_clock WIN2030_CLK_LSP_WDT2_PCLK>;
			clock-names = "pclk";
			resets = <&d1_reset WDT_RST_CTRL SW_WDT_RST_N_2>;
			reset-names = "rst";
			interrupts = <89>;
			interrupt-parent = <&plic1>;
			status = "disabled";
		};

		d1_wdt3: watchdog@0x7080c000 {
			compatible = "snps,dw-wdt";
			reg = <0x0 0x7080c000 0x0 0x4000>;
			clocks =<&d1_clock WIN2030_CLK_LSP_WDT3_PCLK>;
			clock-names = "pclk";
			resets = <&d1_reset WDT_RST_CTRL SW_WDT_RST_N_3>;
			reset-names = "rst";
			interrupts = <90>;
			interrupt-parent = <&plic1>;
			status = "disabled";
		};

		d1_gc820: g2d@70140000 {
			compatible = "eswin,galcore_d1";
			clocks = <&d1_clock WIN2030_CLK_VC_ACLK>,
					<&d1_clock WIN2030_CLK_VC_CFG_CLK>,
					<&d1_clock WIN2030_CLK_G2D_CFG_CLK>,
					<&d1_clock WIN2030_CLK_CLK_G2D_ST2>,
					<&d1_clock WIN2030_CLK_G2D_CLK>,
					<&d1_clock WIN2030_CLK_G2D_ACLK>,
					<&d1_clock WIN2030_CLK_VC_MON_PCLK>;
			clock-names = "vc_aclk", "vc_cfg", "g2d_cfg", "g2d_st2", "g2d_clk", "g2d_aclk","mon_pclk";
			resets = <&d1_reset VC_RST_CTRL SW_VC_AXI_RSTN>,
					<&d1_reset VC_RST_CTRL SW_VC_CFG_RSTN>,
					<&d1_reset VC_RST_CTRL SW_VC_MONCFG_RSTN>,
					<&d1_reset G2D_RST_CTRL SW_G2D_CORE_RSTN>,
					<&d1_reset G2D_RST_CTRL SW_G2D_CFG_RSTN>,
					<&d1_reset G2D_RST_CTRL SW_G2D_AXI_RSTN>;
			reset-names = "axi", "cfg", "moncfg", "g2d_core", "g2d_cfg", "g2d_axi";
			reg = <0 0x70140000 0 0x40000>, <0 0x70180000 0 0x40000>;
			reg-names = "core_2d", "core_2d1";
			fe-apb-offset = <0x800>;
			interrupt-parent = <&plic1>;
			interrupts = <49>, <50>;
			interrupt-names = "core_2d", "core_2d1";
			enable-mmu = <1>;
			contiguous-size = <0xa00000>;
			recovery = <0>;
			dma-noncoherent;
			numa-node-id = <1>;
		};

		d1_sdhci_emmc: mmc@70450000 {
			compatible = "eswin,emmc-sdhci-5.1";
			reg = <0x0 0x70450000 0x0 0x10000>;
			interrupt-parent = <&plic1>;
			interrupts = <79>;
			assigned-clocks = <&d1_clock WIN2030_CLK_HSP_MSHC0_CORE_CLK>;
			assigned-clock-rates = <200000000>;
			clocks = <&d1_clock WIN2030_CLK_HSP_MSHC0_CORE_CLK>, <&d1_clock WIN2030_CLK_HSP_CFG_CLK>;
			clock-names = "clk_xin", "clk_ahb";
			clock-output-names = "d1_emmc_cardclock";
			#clock-cells = <0>;

			resets = <&d1_reset HSPDMA_RST_CTRL SW_MSHC0_TXRX_RSTN>,
				<&d1_reset HSPDMA_RST_CTRL SW_MSHC0_PHY_RSTN>,
				<&d1_reset HSPDMA_RST_CTRL SW_HSP_EMMC_PRSTN>,
				<&d1_reset HSPDMA_RST_CTRL SW_HSP_EMMC_ARSTN>;
			reset-names = "txrx_rst", "phy_rst", "prstn", "arstn";

			core-clk-reg = <0x71828160>;
			disable-cqe-dcmd;
			bus-width = <8>;
			non-removable;
			/* mmc-ddr-1_8v; */
			mmc-hs400-1_8v;
			max-frequency = <200000000>;
			/* sdhci-caps-mask =  <0x0 0x3200000>; */
			/* smmu */
			#size-cells = <2>;
			iommus = <&smmu1 WIN2030_SID_EMMC0>;
			tbus = <WIN2030_TBUID_EMMC>;
			dma-ranges = <0x0 0x00000000 0x0 0xc0000000 0x1 0x0>;
			eswin,hsp_sp_csr = <&d1_hsp_sp_csr 0x1038>;
			status = "disabled";
			numa-node-id = <1>;
			dma-noncoherent;
		};

		d1_graphcard: graphcard {
			compatible = "audio-graph-card";
		};

		d1_usbdrd3_0: usb0@70480000 {
			compatible = "eswin,win2030-dwc3";
			#address-cells = <2>;
			#size-cells = <2>;
			clocks =<&d1_clock WIN2030_GATE_HSP_USB0_SUSPEND_CLK>,
					<&d1_clock WIN2030_CLK_HSP_ACLK>,
					<&d1_clock WIN2030_CLK_HSP_CFG_CLK>;
			clock-names = "suspend","aclk", "cfg_clk";
			eswin,hsp_sp_csr = <&d1_hsp_sp_csr 0x800 0x808 0x83c 0x840>;
			resets = <&d1_reset HSPDMA_RST_CTRL SW_USB0_VAUX_RSTN>;
			reset-names = "vaux";
			ranges;
			status = "disabled";
			d1_usbdrd_dwc3_0: dwc3@70480000 {
				compatible = "snps,dwc3";
				reg = <0x0 0x70480000 0x0 0x10000>;
				#address-cells = <2>;
				#size-cells = <2>;
				interrupt-parent = <&plic1>;
				interrupts = <85>;
				interrupt-names = "peripheral";
				dr_mode = "peripheral";
				phy_type = "utmi";
				maximum-speed = "high-speed";
 				iommus = <&smmu1 WIN2030_SID_USB0>;
				eswin,hsp_sp_csr = <&d1_hsp_sp_csr 0x1044>;
				dma-ranges = <0x0 0x0 0x0 0xc0000000 0x200 0x0>;
				snps,dis_enblslpm_quirk;
				snps,dis-u2-freeclk-exists-quirk;
				snps,dis_u2_susphy_quirk;
				snps,dis-del-phy-power-chg-quirk;
				snps,parkmode-disable-ss-quirk;
				status = "disabled";
				numa-node-id = <1>;
				tbus = <WIN2030_TBUID_USB>;
				dma-noncoherent;
			};
		};

		d1_usbdrd3_1: usb1@70490000 {
			compatible = "eswin,win2030-dwc3";
			#address-cells = <2>;
			#size-cells = <2>;
			clocks =<&d1_clock WIN2030_GATE_HSP_USB1_SUSPEND_CLK>,
					<&d1_clock WIN2030_CLK_HSP_ACLK>,
					<&d1_clock WIN2030_CLK_HSP_CFG_CLK>;
			clock-names = "suspend","aclk", "cfg_clk";
			eswin,hsp_sp_csr = <&d1_hsp_sp_csr 0x900 0x908 0x93c 0x940>;
			resets = <&d1_reset HSPDMA_RST_CTRL SW_USB1_VAUX_RSTN>;
			reset-names = "vaux";
			ranges;
			status = "disabled";
			d1_usbdrd_dwc3_1: dwc3@70490000 {
				compatible = "snps,dwc3";
				reg = <0x0 0x70490000 0x0 0x10000>;
				#address-cells = <2>;
				#size-cells = <2>;
				interrupt-parent = <&plic1>;
				interrupts = <86>;
				interrupt-names = "host";
				dr_mode = "host";
				phy_type = "utmi";
				maximum-speed = "high-speed";
				iommus = <&smmu1 WIN2030_SID_USB1>;
				eswin,hsp_sp_csr = <&d1_hsp_sp_csr 0x1048>;
				dma-ranges = <0x0 0x0 0x0 0xc0000000 0x200 0x0>;
				snps,dis_enblslpm_quirk;
				snps,dis-u2-freeclk-exists-quirk;
				snps,dis_u2_susphy_quirk;
				snps,dis-del-phy-power-chg-quirk;
				snps,parkmode-disable-ss-quirk;
				status = "disabled";
				numa-node-id = <1>;
				tbus = <WIN2030_TBUID_USB>;
				dma-noncoherent;
			};
		};

		d1_vi_top_csr: vi_common_top_csr@0x71030000 {
			compatible = "esw,vi-common-csr", "syscon";
			clocks = <&d1_clock WIN2030_CLK_VI_ACLK>,
					 <&d1_clock WIN2030_CLK_VI_CFG_CLK>,
					 <&d1_clock WIN2030_CLK_VI_DIG_ISP_CLK>,
					 <&d1_clock WIN2030_CLK_VI_DVP_CLK>,
					 <&d1_clock WIN2030_CLK_VI_PHY_CFG>,
					 <&d1_clock WIN2030_CLK_VI_PHY_TXCLKESC>,
					 <&d1_clock WIN2030_CLK_VI_SHUTTER_0>,
					 <&d1_clock WIN2030_CLK_VI_SHUTTER_1>,
					 <&d1_clock WIN2030_CLK_VI_SHUTTER_2>,
					 <&d1_clock WIN2030_CLK_VI_SHUTTER_3>,
					 <&d1_clock WIN2030_CLK_VI_SHUTTER_4>,
					 <&d1_clock WIN2030_CLK_VI_SHUTTER_5>,
					 <&d1_clock WIN2030_MUX_U_VI_ACLK_ROOT_2MUX1_GFREE>,
					 <&d1_clock WIN2030_MUX_U_VI_DVP_ROOT_2MUX1_GFREE>,
					 <&d1_clock WIN2030_MUX_U_VI_DIG_ISP_ROOT_2MUX1_GFREE>,
					 <&d1_clock WIN2030_SPLL0_FOUT1>,
					 <&d1_clock WIN2030_VPLL_FOUT1>;
			clock-names = "aclk", "cfg_clk", "isp_aclk", "dvp_clk", "phy_cfg",
						  "phy_escclk", "sht0", "sht1", "sht2", "sht3", "sht4",
						  "sht5", "aclk_mux", "dvp_mux", "isp_mux", "spll0_fout1", "vpll_fout1";
			resets = <&d1_reset VI_RST_CTRL SW_VI_AXI_RSTN>,
					 <&d1_reset VI_RST_CTRL SW_VI_CFG_RSTN>,
					 <&d1_reset ISP0_RST_CTRL SW_VI_ISP0_RSTN>,
					 <&d1_reset ISP1_RST_CTRL SW_VI_ISP1_RSTN>,
					 <&d1_reset DVP_RST_CTRL SW_VI_DVP_RSTN>,
					 <&d1_reset SHUTTER_RST_CTRL SW_VI_SHUTTER_RSTN_0>,
					 <&d1_reset SHUTTER_RST_CTRL SW_VI_SHUTTER_RSTN_1>,
					 <&d1_reset SHUTTER_RST_CTRL SW_VI_SHUTTER_RSTN_2>,
					 <&d1_reset SHUTTER_RST_CTRL SW_VI_SHUTTER_RSTN_3>,
					 <&d1_reset SHUTTER_RST_CTRL SW_VI_SHUTTER_RSTN_4>,
					 <&d1_reset SHUTTER_RST_CTRL SW_VI_SHUTTER_RSTN_5>;
			reset-names = "axi", "cfg", "isp0", "isp1", "dvp", "sht0", "sht1", "sht2", "sht3", "sht4", "sht5";

			id = <0>;
			#size-cells = <2>;
			reg = <0x0 0x71030000 0x0 0x10000>;
		};

		d1_isp_0: isp@0x71000000 {
			compatible = "esw,win2030-isp";
			reg = <0x0 0x71000000 0x0 0x10000>;
			interrupts = <21 19 20>;
			interrupt-parent = <&plic1>;
			id = <0>;
			#size-cells = <2>;
			dma-ranges = <0x0 0x20000000 0x0 0x80000000 0x0 0x40000000>;
			iommus = <&smmu1 WIN2030_SID_ISP0>;
			eswin,vi_top_csr = <&d1_vi_top_csr 0x1000>;
			numa-node-id = <1>;
			dma-noncoherent;
		};

		d1_isp_1: isp@0x71010000 {
			compatible = "esw,win2030-isp";
			reg = <0x0 0x71010000 0x0 0x10000>;
			interrupts = <24 22 23>;
			interrupt-parent = <&plic1>;
			id = <1>;
			#size-cells = <2>;
			dma-ranges = <0x0 0x20000000 0x0 0x80000000 0x0 0x40000000>;
			iommus = <&smmu1 WIN2030_SID_ISP1>;
			eswin,vi_top_csr = <&d1_vi_top_csr 0x1004>;
			numa-node-id = <1>;
			dma-noncoherent;
		};

		d1_dewarp: dewarp@71020000 {
			compatible = "eswin,dewarp";
			clocks = <&d1_clock WIN2030_CLK_VI_ACLK>,
					 <&d1_clock WIN2030_CLK_VI_CFG_CLK>,
					 <&d1_clock WIN2030_CLK_VI_DIG_DW_CLK>,
					 <&d1_clock WIN2030_MUX_U_VI_ACLK_ROOT_2MUX1_GFREE>,
					 <&d1_clock WIN2030_MUX_U_VI_DW_ROOT_2MUX1>,
					 <&d1_clock WIN2030_SPLL0_FOUT1>,
					 <&d1_clock WIN2030_VPLL_FOUT1>;
			clock-names = "aclk", "cfg_clk", "dw_aclk", "aclk_mux", "dw_mux", "spll0_fout1", "vpll_fout1";
			resets = <&d1_reset VI_RST_CTRL SW_VI_AXI_RSTN>,
					 <&d1_reset VI_RST_CTRL SW_VI_CFG_RSTN>,
					 <&d1_reset VI_RST_CTRL SW_VI_DWE_RSTN>;
			reset-names = "axi", "cfg", "dwe";

			interrupt-parent = <&plic1>;
			interrupts = <26 25>;
			#size-cells = <2>;
			dma-ranges = <0x0 0x20000000 0x0 0x80000000 0x0 0x40000000>;
			iommus = <&smmu1 WIN2030_SID_DW>;
			tbus = <WIN2030_TBUID_DW>;
			eswin,vi_top_csr = <&d1_vi_top_csr 0x1008>;
			reg = <0x0 0x71020000 0x0 0xc00>, <0x0 0x71020c00 0x0 0x120>;
			numa-node-id = <1>;
			dma-noncoherent;
		};

		d1_mipi_dphy_rx: dphy@710c0000 {
			compatible = "snps,dw-dphy-rx";
			#phy-cells = <1>;
			bus-width = <8>;
			snps,dphy-frequency = <300000>;
			snps,phy_type = <8>;
			reg = <0x0 0x710c0000 0x0 0x20000>;
			numa-node-id = <1>;
		};

		d1_csi_dma0: csidma@0x72048000 {
			compatible = "eswin,csi-video";
			interrupt-parent = <&plic1>;
			interrupts = <29>;
			reg = <0x0 0x72048000 0x0 0x1000>;
			numa-node-id = <1>;

			port {
				#address-cells = <1>;
				#size-cells = <0>;

				d1_csi_dmar_0: endpoint@0 {
					reg = <0>;
					bus-type = <4>;
					remote-endpoint = <&d1_csi2_dma_0_3>;
				};
			};
		};

		d1_csi_dma1: csidma@0x72058000 {
			compatible = "eswin,csi-video";
			interrupt-parent = <&plic1>;
			interrupts = <30>;
			reg = <0x0 0x72058000 0x0 0x1000>;
			numa-node-id = <1>;

			port {
				#address-cells = <1>;
				#size-cells = <0>;

				d1_csi_dmar_1: endpoint@0 {
					reg = <0>;
					bus-type = <4>;
					remote-endpoint = <&d1_csi2_dma_1_3>;
				};
			};
		};

		d1_csi2_0: csi2@71050000 {
			compatible = "snps,dw-csi";
			#address-cells = <1>;
			#size-cells = <0>;
			interrupt-parent = <&plic1>;
			interrupts = <29>;
			snps,output-type = <0>;
			reg = <0x0 0x71050000 0x0 0x1000>;
			/*phys = <&mipi_dphy_rx 1>;*/
			numa-node-id = <1>;

			/* MIPI CONFIG */
			snps,en-ppi-width = <0>;/* 0: ppi8, 1: ppi16 */
			snps,en-phy-mode = <0>;/* 0: D-PHY, 1: C-PHY */

			ipi2_en = <0>;/* for virtual channel */
			ipi2_vcid = <0>;/* virtual channel id */
			ipi3_en = <0>;
			ipi3_vcid = <0>;

			#ifdef MIPI_CSI2_IMX290_ENBALE
			port@1 {
				reg = <1>;
				d1_csi2_0_1: endpoint {
					bus-type = <4>;
					clock-lanes = <0>;
					#ifdef MIPI_CSI2_2LINE_ENABLE
					data-lanes = <1 2>;
					#else
					data-lanes = <1 2 3 4>;
					#endif
					//remote-endpoint = <&imx290_csi2>;
				};
			};
			#endif

			port@2 {
				reg = <2>;
				d1_csi2_dma_0_3: endpoint {
					bus-type = <5>;
					remote-endpoint = <&d1_csi_dmar_0>;
				};
			};
		};

		d1_csi2_1: csi2@71060000 {
			compatible = "snps,dw-csi";
			#address-cells = <1>;
			#size-cells = <0>;
			interrupt-parent = <&plic1>;
			interrupts = <30>;
			snps,output-type = <0>;
			reg = <0x0 0x71060000 0x0 0x1000>;
			/*phys = <&mipi_dphy_rx 1>;*/
			numa-node-id = <1>;

			/* MIPI CONFIG */
			snps,en-ppi-width = <0>;/* 0: ppi8, 1: ppi16 */
			snps,en-phy-mode = <0>;/* 0: D-PHY, 1: C-PHY */

			ipi2_en = <0>;/* for virtual channel */
			ipi2_vcid = <0>;/* virtual channel id */
			ipi3_en = <0>;
			ipi3_vcid = <0>;

			#ifdef MIPI_CSI2_IMX290_ENBALE
			port@1 {
				reg = <1>;
				d1_csi2_1_1: endpoint {
					bus-type = <4>;
					clock-lanes = <0>;
					#ifdef MIPI_CSI2_2LINE_ENABLE
					data-lanes = <1 2>;
					#else
					data-lanes = <1 2 3 4>;
					#endif
					//remote-endpoint = <&imx290_csi2>;
				};
			};
			#endif

			port@2 {
				reg = <2>;
				d1_csi2_dma_1_3: endpoint {
					bus-type = <5>;
					remote-endpoint = <&d1_csi_dmar_1>;
				};
			};
		};

		d1_dc_test: dctest@702c0000 {
			compatible = "eswin,dc";
			reg = <0x0 0x702c0000 0x0 0x10000>;
			interrupt-parent = <&plic1>;
			interrupts = <238>;
		};

		d1_numa_sample:numa_sample@1 {
			compatible = "eswin,numa-sample","simple-bus";
			#address-cells = <2>;
			#size-cells = <2>;
			ranges;
			dma-ranges = <0x0 0x80000000 0x0 0xc0000000 0x0 0x80000000>;
			iommus = <&smmu1 WIN2030_SID_SCPU>;
			numa-node-id = <1>;
			dma-noncoherent;
		};

		d1_ddr0: ddr-controller@72300000 {
			compatible = "eswin,ddrc-1.20a";
			interrupt-parent = <&plic1>;
			interrupts = <10>;
			interrupt-names = "ddr-ecc";
			reg = <0x0 0x72300000 0x0 0x40000>;
			ctrl-id = <0>;
			numa-node-id = <1>;
			status = "disabled";
		};

		d1_ddr1: ddr-controller@72380000 {
			compatible = "eswin,ddrc-1.20a";
			interrupt-parent = <&plic1>;
			interrupts = <299>;
			interrupt-names = "ddr-ecc";
			reg = <0x0 0x72380000 0x0 0x40000>;
			ctrl-id = <1>;
			numa-node-id = <1>;
			status = "disabled";
		};

		d1_d2d: d2d-unit@72100000 {
			compatible = "eswin,eic7x-d2d";
			interrupt-parent = <&plic1>;
			interrupts = <287>, <288>;
			reg = <0x0 0x72100000 0x0 0x50000>;
			reg-names = "control";
			numa-node-id = <1>;
			status = "disabled";
		};
};

